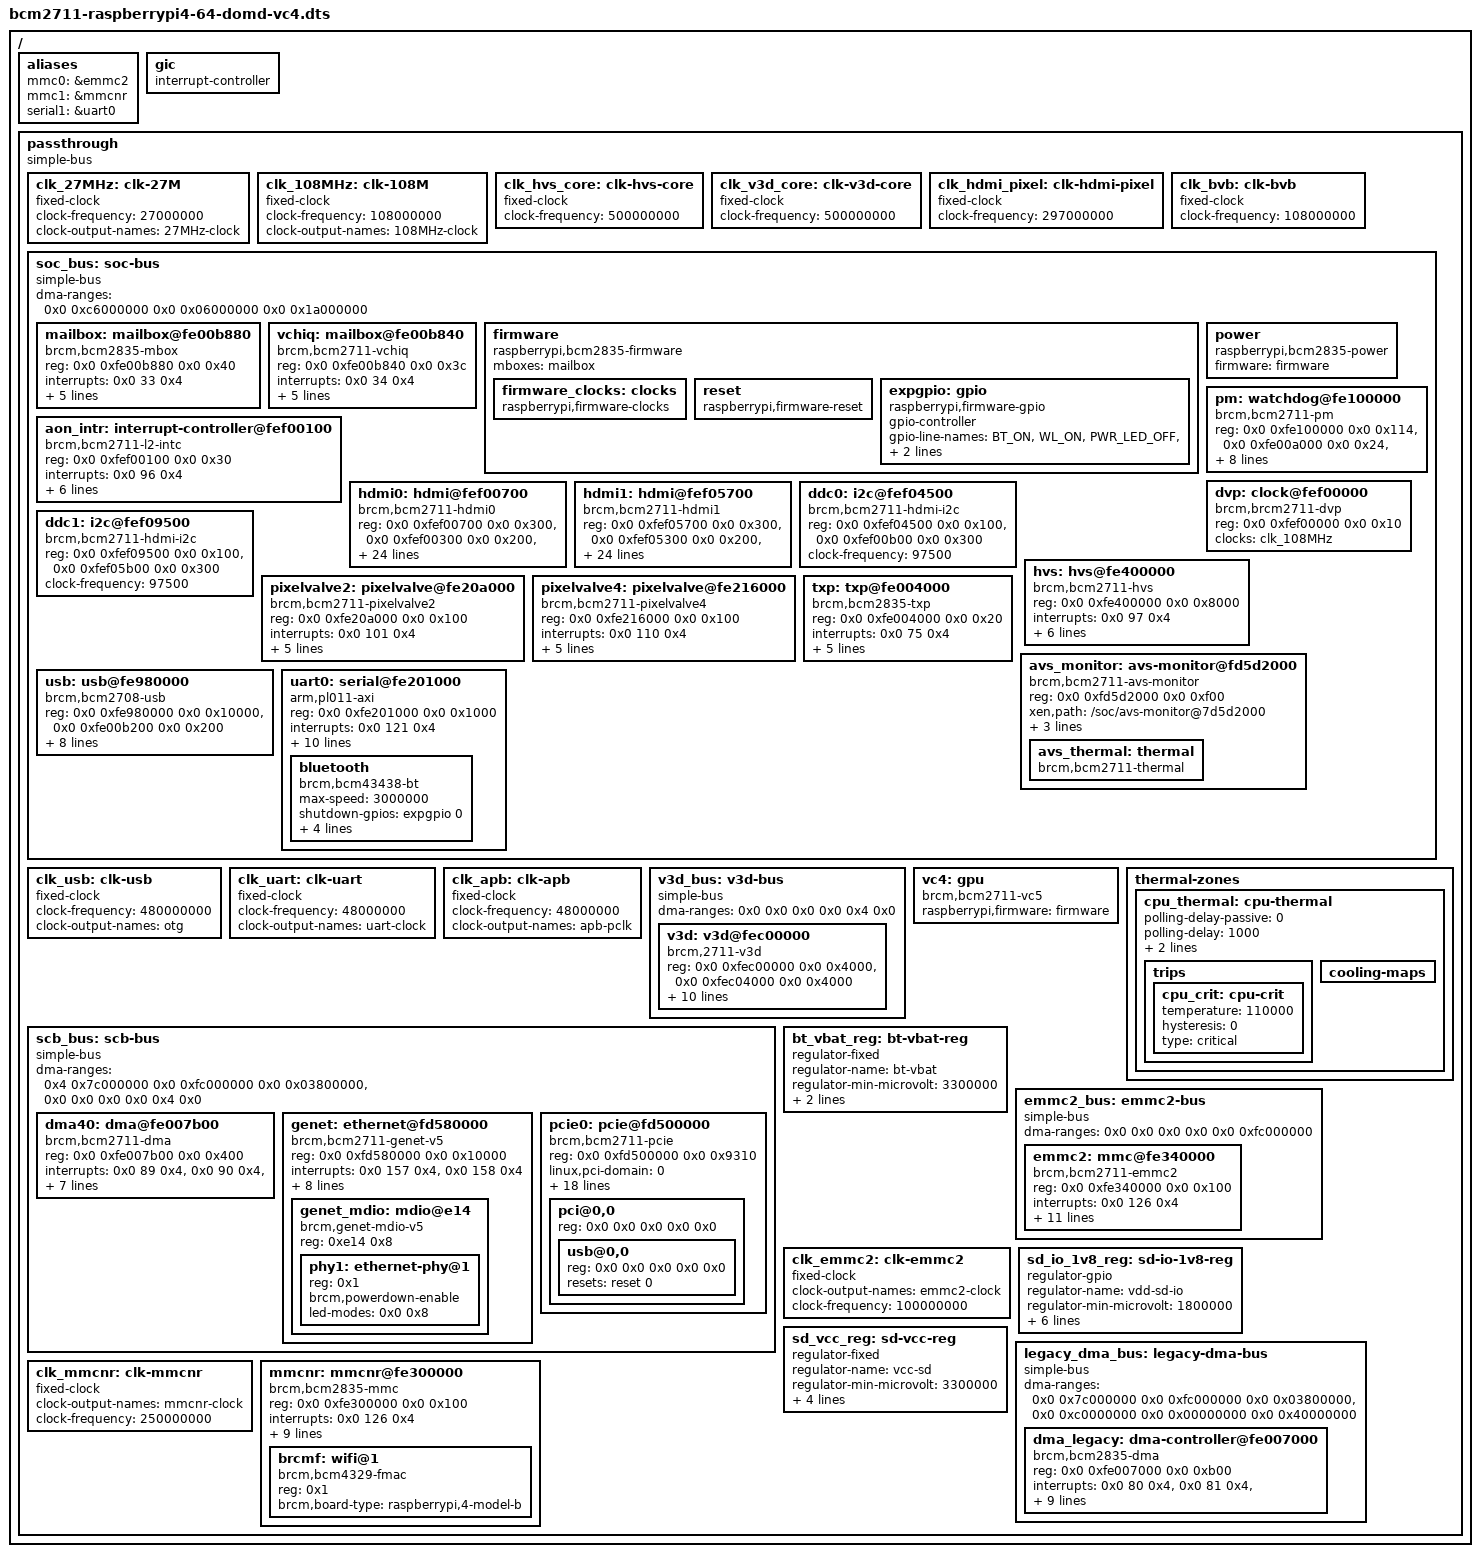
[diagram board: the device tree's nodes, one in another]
/*
 * BCM2711 / Raspberry Pi 4 — DomD (vc4 driver domain) partial device tree
 *
 * Copyright (c) 2026 Yuichi Kusakabe
 *
 * SPDX-License-Identifier: Apache-2.0
 *
 * Architecture: control Dom0 (Zephyr or thin Linux) + dom0less direct-mapped
 * DomD that owns the whole display/GPU complex, and — in the Zephyr flavour —
 * the SD controller as well.
 *
 * ===========================================================================
 * Source of truth
 * ===========================================================================
 * Every address, size and GIC SPI below was read out of the shipped
 * bcm2711-rpi-4-b.dtb (see ../../../../BCM2711-DT-TRUTH.md), NOT translated
 * from the BCM2712 version. Bus translation applied:
 *   /soc      1/1  0x7e000000 -> 0xfe000000, 0x7c000000 -> 0xfc000000,
 *                  0x40000000 -> 0xff800000
 *   /emmc2bus 2/1  0x7e000000 -> 0xfe000000
 *   /scb      2/2  0x7c000000 -> 0xfc000000 (so 0x7d500000 -> 0xfd500000)
 *   /v3dbus   1/2  0x7c500000 -> 0xfc500000 (so 0x7ec00000 -> 0xfec00000)
 * BCM2711 is a 35-bit map and every MMIO block lands below 4 GiB, so all
 * addresses here are plain 32-bit values in 2-cell form — none of the BCM2712
 * `0x10_7c......` 40-bit forms remain.
 *
 * ===========================================================================
 * xen,reg / xen,path rules honoured here (xen/common/device-tree/dom0less-build.c)
 * ===========================================================================
 *  - xen,reg = <host_pbase size guest_gbase>, ALL page-aligned. Identity
 *    mapping (guest IPA == host PA) because DomD is direct-map.
 *  - a node with xen,path MUST also have xen,reg (else -EINVAL), and the IRQs
 *    of the *host* node named by xen,path are what get routed to DomD.
 *  - every host page is mapped exactly ONCE across the whole partial DT, with
 *    TWO deliberate exceptions: page 0xfe00b000, declared identically by
 *    mailbox@fe00b880 and by vchiq (mailbox@fe00b840), and page 0xfe007000,
 *    declared identically by the legacy DMA engine (dma-controller@fe007000)
 *    and by dma40 (dma@fe007b00).
 *    Single ownership is OUR rule, not Xen's: a duplicate xen,reg does not fail,
 *    because map_regions_p2mt() -> p2m_insert_mapping() -> p2m_set_entry()
 *    (xen/arch/arm/p2m.c:113) overwrites the existing entry. It matters because a
 *    page mapped twice usually means two nodes each believe they own it, and the
 *    second one's intent is silently discarded. Devices sharing a 4 KiB page are
 *    therefore represented as one "owner" node carrying xen,path+xen,reg plus
 *    plain sibling nodes with no xen,* properties at all.
 *    Both exceptions are forced rather than chosen: each second node has GIC
 *    SPIs OF ITS OWN (vchiq 34 against the firmware mailbox's 33; dma40 89-92
 *    against the legacy engine's 80-88), Xen routes a node's IRQs only from
 *    the xen,path branch of handle_passthrough_prop(), and its caller rejects a
 *    xen,path without xen,reg with -EINVAL, which panics domain construction.
 *    There is no way to say "route the IRQ, the MMIO is already mapped". See the
 *    note on vchiq's xen,reg for why repeating the mapping is safe.
 *  - IRQs whose interrupt-parent is not the GIC are skipped by Xen
 *    (map_interrupts_to_domain), so the HDMI L2 sub-IRQs need no GIC grant —
 *    only their L2 parent (aon_intr, GIC SPI 96) does.
 *
 * ===========================================================================
 * DMA: the central BCM2711 difference
 * ===========================================================================
 * BCM2711 has no IOMMU and its legacy peripherals address DRAM through the
 * VideoCore bus alias at 0xc0000000, limited to the low 1 GiB. Read the values
 * from the RUNNING tree, not from bcm2711-rpi-4-b.dtb: the firmware rewrites
 * some of them before boot (`fdt print /soc` / `/emmc2bus` at the U-Boot
 * prompt). What the two look like on a 4 GiB board:
 *     /soc      dma-ranges = <0xc0000000 0x0 0x0 0x40000000>   (alias, low 1 GiB)
 *                            <0x7c000000 0x0 0xfc000000 0x3800000>
 *     /emmc2bus dma-ranges = <0x0 0x0 0x0 0x0 0xfc000000>      (IDENTITY, 3.94 GiB)
 * The file ships <0x0 0xc0000000 0x0 0x0 0x40000000> for /emmc2bus; the
 * firmware replaces it. So a dma_addr handed to the VideoCore or the HVS must
 * be (phys + 0xc0000000) with phys < 1 GiB, but one handed to emmc2 is the
 * plain physical address -- see the note at emmc2_bus below for what carrying
 * the pre-fixup alias to emmc2 did on hardware. GENET (/scb, 16 GiB) and V3D
 * (/v3dbus, own MMU) are identity-mapped and unrestricted.
 *
 * That is modelled with four intermediate simple-bus wrappers, each carrying
 * only the dma-ranges its children need (MMIO stays identity via `ranges;`):
 *     soc_bus                ->  <0x0 0xc6000000  0x0 0x06000000  0x0 0x1a000000>
 *                                bus 0xc6000000 == phys 0x06000000, 416 MiB
 *     emmc2_bus              ->  <0x0 0x0  0x0 0x0  0x0 0xfc000000>
 *                                identity, as the firmware-fixed host DT has it
 *     legacy_dma_bus         ->  <0x0 0x7c000000  0x0 0xfc000000  0x0 0x03800000>,
 *                                <0x0 0xc0000000  0x0 0x00000000  0x0 0x40000000>
 *                                the host /soc pair verbatim: peripherals as the
 *                                VideoCore sees them, plus the DRAM alias
 *     scb_bus   / v3d_bus    ->  identity
 * 0x06000000+0x1a000000 covers DomD static-mem bank1 on both SKUs, the only DomD
 * RAM the VideoCore can see: it IS bank1 on the 4 GiB map (set by the boot
 * script's board_ram block) and contains the 8 GiB map's 0x08000000+384 MiB
 * (bcm2711-raspberrypi4-64-xen.dtso). Only the start moved down; the end, and
 * with it the tree minimum in (a) below, is still 0x20000000.
 * legacy_dma_bus is a bus of its own rather than a second dma-ranges entry on
 * soc_bus because of_dma_get_max_cpu_address() takes the MAXIMUM of cpu_addr+size
 * WITHIN a node but the MINIMUM ACROSS nodes: this bus's own maximum is
 * 0xff7fffff, higher than soc_bus's 0x1fffffff, so the tree minimum -- and with it
 * consequence (a) below -- does not move. Widening soc_bus instead would move it
 * and would break scanout.
 *
 * Two consequences we rely on:
 *   a) of_dma_get_max_cpu_address() takes the MINIMUM dma-ranges limit found
 *      anywhere in the tree, so arm64_dma_phys_limit becomes 0x20000000 and
 *      dma_contiguous_reserve() places vc4's CMA inside bank1 automatically.
 *      No `cma=<n>@<addr>` pinning is required — only `cma=<n>`.
 *   b) vc4_drm_bind() does not use its own node's DMA properties: it calls
 *      of_dma_configure(dev, node, true) on the first node matching
 *      vc4_dma_range_matches[], and on BCM2711 the only entry present is
 *      "brcm,bcm2711-hvs". So the DRM device — and therefore every dumb/CMA
 *      buffer object weston allocates — inherits the dma-ranges of whatever
 *      bus the HVS node sits under. Keeping hvs inside soc_bus is what makes
 *      display buffers land in the VideoCore-reachable window with the correct
 *      0xc0000000 bus alias; moving it out would silently break scanout.
 *
 * NOTE on 3D: on BCM2711 vc4_v3d_dt_match[] does NOT list "brcm,2711-v3d", so
 * vc4 is display-only here (no DRIVER_RENDER) and the separate drivers/gpu/drm/
 * v3d driver owns the 3D core, exposing renderD128 alongside vc4's card0. That
 * matches native RPi4 and is what Mesa expects.
 * ===========================================================================
 */

/dts-v1/;

/ {
	#address-cells = <0x2>;
	#size-cells = <0x2>;

	/*
	 * Root-level /gic and /hypervisor are NOT copied into the guest DT:
	 * domain_handle_dtb_boot_module() only scans the partial DT's `aliases`
	 * and `passthrough` nodes. They exist purely so dtc can resolve the
	 * <&gic> references inside /passthrough at build time.
	 *
	 * The phandle is hard-coded to GUEST_PHANDLE_GIC (65000 = 0xfde8) from
	 * xen/include/public/device_tree_defs.h because THIS FRAGMENT IS ALSO
	 * MEANT FOR libxl: a domd.cfg names it in `device_tree =` (this board
	 * installs none; README "No domd.cfg on this board"), and libxl gives
	 * the GIC node it generates a hard-coded GUEST_PHANDLE_GIC
	 * (libxl_arm.c make_gicv{2,3}_node()). A lower value would leave every
	 * interrupt-parent inside /passthrough pointing at a non-existent node
	 * on that path -> no IRQs in DomD -> vc4-drm never binds.
	 *
	 * On the dom0less path the value is NOT required to be 65000: Xen reads
	 * it back from this node (init_intc_phandle()) and gives its generated
	 * vGIC the same phandle -- GUEST_PHANDLE_GIC is merely the default
	 * prepare_dtb_domU() starts from. Xen 4.22 then REJECTS a fragment whose
	 * highest phandle is in the reserved range ("Device tree generation
	 * failed (-75)", panic, reboot loop); that is an upstream regression
	 * fixed here by xen patch 4.22-0006, not a reason to change this value.
	 */
	/*
	 * serial1 = the REAL pl011, so that Xen's emulated vpl011 keeps ttyAMA0 —
	 * which is what DomD's bootargs say (console=ttyAMA0).
	 *
	 * DomD ends up with two pl011-family ports: Xen's vpl011, which appears in
	 * the generated guest DT as /sbsa-uart@<base> with compatible
	 * "arm,sbsa-uart" (xen/arch/arm/dom0less-build.c:181-185), and the physical
	 * one below. Both are handled by amba-pl011.c and both allocate out of the
	 * same amba_ports[] array, so without a hint the index is
	 * first-come-first-served.
	 *
	 * pl011_setup_port() calls pl011_probe_dt_alias() (amba-pl011.c:2780-2809),
	 * which honours a "serialN" alias and falls back to the caller's index
	 * otherwise. sbsa_uart_probe() has no alias entry, so it takes
	 * pl011_find_free_port() = the lowest free slot. Pinning the physical port to
	 * 1 therefore gives vpl011 slot 0 in either probe order. Measured on the
	 * board: the physical port comes up as ttyAMA1 and hci0 binds under
	 * fe201000.serial, while DomD's console stays on ttyAMA0. (An "aliased and
	 * non-aliased serial devices" warning is expected and harmless.)
	 *
	 * Xen copies this node across: domain_handle_dtb_boot_module() scans exactly
	 * `aliases` and `passthrough` in the partial DT. dtc turns the &label into
	 * the node's full path string.
	 *
	 * &uart0 lives OUTSIDE the SD-STRIP block near the end of this file, so this
	 * reference survives the DOM0_OS=linux strip.
	 */
	aliases {
		/* SODEV-LINUX-DOM0-SD-STRIP-BEGIN: these TWO LINES ONLY.
		 * Pin the mmc host index. Linux assigns it in mmc_alloc_host() from
		 * of_alias_get_id(dev->of_node, "mmc") and only falls back to
		 * first-come-first-served when there is no alias. DomD boots with
		 * root=/dev/mmcblk0p2, so emmc2 MUST be mmc0; without this the mmcnr
		 * below probes first, takes index 0, the SD card slides to mmcblk1 and
		 * `rootwait` waits forever with no error printed:
		 *
		 *     mmc0: SDHCI controller on fe300000.mmcnr ... using PIO
		 *     mmc1: SDHCI controller on fe340000.mmc ... using ADMA
		 *     mmcblk1: mmc1:d555 ST512 456 GiB
		 *     Waiting for root device /dev/mmcblk0p2...
		 *
		 * The host DT pins the same two (mmc0 = /emmc2bus/mmc@7e340000,
		 * mmc1 = /soc/mmcnr@7e300000); this mirrors it.
		 *
		 * &emmc2 and &mmcnr are both declared inside the big SD-STRIP block near
		 * the end of this file, so for DOM0_OS=linux domd-vc4.bb deletes the
		 * nodes and these two references would be left dangling. dtc then
		 * refuses the whole tree --
		 *     ERROR (path_references): /aliases: Reference to non-existent node
		 *                              or label "emmc2"
		 * -- and do_compile produces no DTB at all.
		 *
		 * JUST these two lines are marked, and NOT the whole /aliases node:
		 * serial1 below points at &uart0, which lives outside the strip block
		 * and is load-bearing for Bluetooth. domd-vc4.bb's sed is
		 * `/BEGIN/,/END/d`, which deletes EVERY BEGIN..END range it finds, so a
		 * second pair here needs no recipe change. Comments are dropped by dtc,
		 * so the zephyr DTB is unaffected by the markers themselves.
		 */
		mmc0 = &emmc2;
		mmc1 = &mmcnr;
		/* SODEV-LINUX-DOM0-SD-STRIP-END */
		serial1 = &uart0;
	};

	gic: gic {
		#interrupt-cells = <0x3>;
		interrupt-controller;
		phandle = <0xfde8>;
		linux,phandle = <0xfde8>;
	};

	passthrough: passthrough {
		/*
		 * The Xen partial-DT spec (xen/docs/misc/arm/passthrough.txt)
		 * mandates compatible="simple-bus" here; Linux's
		 * of_platform_default_populate() also needs it to enumerate the
		 * children as platform devices.
		 */
		compatible = "simple-bus";
		ranges;
		#address-cells = <0x2>;
		#size-cells = <0x2>;

		/* ==============================================================
		 * Fixed clocks (root-level on the host DT; the partial-DT spec
		 * allows them under /passthrough because they have no MMIO).
		 * ============================================================== */
		clk_27MHz: clk-27M {
			compatible = "fixed-clock";
			#clock-cells = <0>;
			clock-frequency = <27000000>;
			clock-output-names = "27MHz-clock";
		};

		clk_108MHz: clk-108M {
			compatible = "fixed-clock";
			#clock-cells = <0>;
			clock-frequency = <108000000>;
			clock-output-names = "108MHz-clock";
		};

		/*
		 * Fallback fixed-clocks for the display path. NOT wired by
		 * default: unlike BCM2712 (where raspberrypi-clk probe failed
		 * with -22 and the RPi5 port had to fake every clock), BCM2711
		 * natively drives HVS/V3D/HDMI from <&firmware_clocks N> and the
		 * mbox-bus dma-ranges above is what makes that work inside DomD.
		 * If `raspberrypi-clk` still fails on hardware, swap the
		 * <&firmware_clocks N> references below for these and re-test —
		 * that is the whole fallback, no other change needed.
		 */
		clk_hvs_core: clk-hvs-core {
			compatible = "fixed-clock";
			#clock-cells = <0>;
			clock-frequency = <500000000>;
		};
		clk_v3d_core: clk-v3d-core {
			compatible = "fixed-clock";
			#clock-cells = <0>;
			clock-frequency = <500000000>;
		};
		clk_hdmi_pixel: clk-hdmi-pixel {
			compatible = "fixed-clock";
			#clock-cells = <0>;
			clock-frequency = <297000000>;
		};
		clk_bvb: clk-bvb {
			compatible = "fixed-clock";
			#clock-cells = <0>;
			clock-frequency = <108000000>;
		};

		/* ==============================================================
		 * soc_bus — every /soc device DomD owns.
		 *
		 * dma-ranges gives the VideoCore bus alias (phys + 0xc0000000)
		 * bounded to DomD static-mem bank1 (0x06000000 + 416 MiB on the
		 * 4 GiB map; the 8 GiB map's bank1 is the top 384 MiB of it), the
		 * only DomD RAM below the 1 GiB VideoCore DMA limit. This is the
		 * RPi4 equivalent of the RPi5 "mbox-bus" fix, but it now also
		 * covers HVS (display fetch) and — via emmc2_bus — the SD
		 * controller, because on BCM2711 all three share the same
		 * restriction.
		 * ============================================================== */
		soc_bus: soc-bus {
			compatible = "simple-bus";
			#address-cells = <0x2>;
			#size-cells = <0x2>;
			ranges;
			dma-ranges = <0x0 0xc6000000 0x0 0x06000000 0x0 0x1a000000>;

			/* ---- VideoCore mailbox + firmware interface ---- */
			mailbox: mailbox@fe00b880 {
				compatible = "brcm,bcm2835-mbox";
				reg = <0x0 0xfe00b880 0x0 0x40>;
				interrupts = <0x0 33 0x4>;	/* GIC SPI 33 LEVEL_HIGH */
				interrupt-parent = <&gic>;
				#mbox-cells = <0>;
				xen,path = "/soc/mailbox@7e00b880";
				xen,force-assign-without-iommu;
				/*
				 * Page 0xfe00b000 also holds mailbox@7e00b840
				 * (vchiq) and the dwc2 controller's second reg
				 * block (0xfe00b200), so this one mapping covers
				 * all three; usb@fe980000 below must NOT map it
				 * again. vchiq below DOES repeat it, deliberately
				 * and identically -- see the note on its xen,reg.
				 */
				xen,reg = <0x0 0xfe00b000 0x0 0x1000 0x0 0xfe00b000>;
				status = "okay";
			};

			/* ------------------------------------------------------------------
			 * vchiq -- the VideoCore host interface the H.264 decoder rides on.
			 *
			 * WHY IT IS HERE
			 * The only H.264 decode hardware reachable on BCM2711 is inside
			 * VideoCore, driven through VCHIQ/MMAL by bcm2835-codec, which
			 * presents a V4L2 M2M decoder. Without this node vchiq never binds
			 * (CONFIG_BCM2835_VCHIQ=y, so it waits for the DT node, not for a
			 * module), bcm2835-codec has nothing to talk to, no /dev/videoN
			 * appears, and the virtio-media device DomA is given has no backend.
			 * It also needs dma40 on scb_bus: on BCM2711 vchiq fails its probe
			 * without a brcm,bcm2711-dma node (see there).
			 *
			 * The dedicated codec@7eb10000 block is HEVC-only and is deliberately
			 * NOT added here: nothing on this product decodes HEVC (the guest's
			 * decoder list is H.264 only), so it would be a node added for no user.
			 *
			 * The RPi5 has no vchiq node at all, which is why H.264 hardware
			 * decode is RPi4-only on this platform.
			 *
			 * DELTAS FROM THE HOST NODE /soc/mailbox@7e00b840
			 *
			 *   pinctrl-0   Dropped. The host points at <&audio_pins> under
			 *               gpio@7e200000 -- GPIO 40/41 muxed to ALT0, i.e. the
			 *               analog PWM audio on the headphone jack. That has
			 *               nothing to do with the mailbox transport this node is
			 *               here for, DomA's audio goes out over HDMI, and DomD
			 *               has no GPIO controller to apply it with.
			 *
			 *   xen,reg     Identical to the mailbox node's above, ON PURPOSE.
			 *               vchiq's registers (0xfe00b840 + 0x3c) sit in the same
			 *               4 KiB page as the mailbox's, and there is no way to
			 *               say "route the IRQ, the MMIO is already mapped":
			 *               handle_passthrough_prop()'s caller rejects a
			 *               xen,path without xen,reg with -EINVAL, and -EINVAL
			 *               there panics domain construction. Repeating the same
			 *               mapping is safe on both counts the code cares about:
			 *               map_regions_p2mt() ends in p2m_set_entry(), which
			 *               overwrites an identical GFN->MFN entry rather than
			 *               rejecting it, and the rangeset that tracks assigned
			 *               guest ranges returns 0 for a range already contained
			 *               -- that rangeset only feeds the memory-hole
			 *               subtraction which keeps guest RAM off passthrough
			 *               MMIO, so a duplicate is a no-op there. An empty
			 *               xen,reg would also skip the mapping loop, but only
			 *               because the length computes to 0 -- an unintended
			 *               hole that one upstream length check would turn into a
			 *               panic. If the duplicate is ever refused, Xen says so
			 *               out loud with "Failed to map", which is worth more
			 *               than a quiet trick.
			 *
			 * GIC SPI 34 is this node's alone -- no other host node names it, so
			 * unlike mmcnr/emmc2 on SPI 126 there is no shared-line hazard here.
			 *
			 * The host side needs the matching release: &vchiq in
			 * bcm2711-raspberrypi4-64-xen.dtso. The label `mailbox` resolves to
			 * /soc/mailbox@7e00b880, the FIRMWARE mailbox on SPI 33, and does not
			 * cover this node.
			 * ------------------------------------------------------------------ */
			vchiq: mailbox@fe00b840 {
				compatible = "brcm,bcm2711-vchiq";
				reg = <0x0 0xfe00b840 0x0 0x3c>;
				interrupts = <0x0 34 0x4>;	/* GIC SPI 34 LEVEL_HIGH */
				interrupt-parent = <&gic>;
				xen,path = "/soc/mailbox@7e00b840";
				xen,force-assign-without-iommu;
				xen,reg = <0x0 0xfe00b000 0x0 0x1000 0x0 0xfe00b000>;
				status = "okay";
			};

			firmware: firmware {
				compatible = "raspberrypi,bcm2835-firmware", "simple-mfd";
				#address-cells = <0x1>;
				#size-cells = <0x1>;
				mboxes = <&mailbox>;

				firmware_clocks: clocks {
					compatible = "raspberrypi,firmware-clocks";
					#clock-cells = <0x1>;
				};

				/*
				 * raspberrypi,firmware-reset provides the VL805
				 * xHCI reset (RASPBERRYPI_FIRMWARE_RESET_ID_USB
				 * = 0) that pci@0,0/usb@0,0 needs to make the
				 * firmware reload the VL805 SPI firmware.
				 */
				reset: reset {
					compatible = "raspberrypi,firmware-reset";
					#reset-cells = <0x1>;
				};

				/*
				 * expgpio drives the SD card power / IO-voltage
				 * regulators (sd_vcc_reg / sd_io_1v8_reg) that
				 * emmc2 depends on in the Zephyr flavour.
				 */
				expgpio: gpio {
					compatible = "raspberrypi,firmware-gpio";
					gpio-controller;
					#gpio-cells = <0x2>;
					gpio-line-names = "BT_ON", "WL_ON",
							  "PWR_LED_OFF",
							  "GLOBAL_RESET",
							  "VDD_SD_IO_SEL",
							  "CAM_GPIO",
							  "SD_PWR_ON",
							  "SD_OC_N";
					status = "okay";
				};
			};

			/*
			 * raspberrypi,bcm2835-power — the firmware-backed power
			 * domain provider (host phandle "power", NOT "pm").
			 * dwc2 references <&power 6> (RPI_POWER_DOMAIN_USB).
			 * No MMIO, so no xen,reg is needed.
			 */
			power: power {
				compatible = "raspberrypi,bcm2835-power";
				firmware = <&firmware>;
				#power-domain-cells = <0x1>;
			};

			/*
			 * ---- bcm2835-pm: V3D power domain + reset ----
			 * The host V3D node uses power-domains = <&pm 1>
			 * (BCM2835_POWER_DOMAIN_GRAFX_V3D) and resets =
			 * <&pm 0> (BCM2835_RESET_V3D), both provided by
			 * /soc/watchdog@7e100000. Passing it through is what
			 * actually powers the 3D core: leaving it out makes
			 * dev_pm_domain_attach() defer v3d's probe forever, and
			 * dropping the property instead makes v3d_drv fall back
			 * to requiring a "bridge" reg block that BCM2711 does
			 * not have. The display path (HVS/PV/HDMI) has no power
			 * domain on BCM2711 and is unaffected either way.
			 *
			 * Three separate host pages: pm 0xfe100000,
			 * asb 0xfe00a000, rpivid_asb 0xfec11000.
			 */
			pm: watchdog@fe100000 {
				compatible = "brcm,bcm2711-pm", "brcm,bcm2835-pm-wdt";
				#power-domain-cells = <0x1>;
				#reset-cells = <0x1>;
				reg = <0x0 0xfe100000 0x0 0x114>,
				      <0x0 0xfe00a000 0x0 0x24>,
				      <0x0 0xfec11000 0x0 0x20>;
				reg-names = "pm", "asb", "rpivid_asb";
				/*
				 * bcm2835-power fetches its clocks with
				 * devm_clk_get_optional(dev->parent, name), so
				 * peri_image/h264/isp may simply be absent —
				 * DomD drives neither the codecs nor the ISP,
				 * and providing them would mean pulling cprman
				 * (and its clk-osc + dsi0/dsi1 PHY clock
				 * providers) into the driver domain for nothing.
				 * Only "v3d" is wired, from the firmware clock.
				 */
				clocks = <&firmware_clocks 5>;
				clock-names = "v3d";
				/*
				 * Deliberately NO system-power-controller: the
				 * host node has it, but a driver domain must not
				 * be able to reset the whole board.
				 */
				xen,path = "/soc/watchdog@7e100000";
				xen,force-assign-without-iommu;
				xen,reg = <0x0 0xfe100000 0x0 0x1000 0x0 0xfe100000>,
					  <0x0 0xfe00a000 0x0 0x1000 0x0 0xfe00a000>,
					  <0x0 0xfec11000 0x0 0x1000 0x0 0xfec11000>;
				status = "okay";
			};

			/*
			 * ---- Display/HDMI L2 interrupt controller ----
			 * BCM2711 has exactly ONE L2 controller in the display
			 * area (/soc/interrupt-controller@7ef00100, host label
			 * "aon_intr"), GIC SPI 96, LEVEL_HIGH. BCM2712's
			 * disp_intr / bsc_irq / mop / moplet have no BCM2711
			 * equivalent, and BCM2711's HVS is wired straight to the
			 * GIC instead.
			 *
			 * The type is LEVEL_HIGH, matching mainline Linux (which
			 * has said so since at least v5.19) and raspberrypi/linux
			 * from rpi-6.1.y onwards, including the 6.18 pinned here.
			 * It is NOT edge, despite what the bcm2711-rpi-4-b.dtb
			 * that raspberrypi/firmware distributes still says: that
			 * prebuilt carries the pre-6.1 EDGE_RISING value and is
			 * simply stale. rpi-5.10.y/5.15.y had EDGE_RISING too.
			 *
			 * This is load-bearing, measured on hardware 2026-09-02.
			 * The brcmstb-l2 driver masks all 32 child sources and
			 * clears their status at the top of its probe, so the
			 * controller's output line is low by the time it chains
			 * the parent. With a level type that means no pending
			 * parent and the probe finishes quietly. With an edge
			 * type a rising edge latched earlier -- during the
			 * firmware's HDMI/EDID work, before Linux runs -- stays
			 * pending regardless of the line, gets re-sent the moment
			 * irq_set_chained_handler_and_data() starts the parent,
			 * and DomD dies in an initcall with
			 *   brcmstb_l2_intc_irq_handle+0x40
			 *   Kernel panic: Fatal exception in interrupt
			 * (the handler's first dereference happens before the
			 * driver assigns data->gc; see the 0013 patch in
			 * meta-xt-driver-domain, which closes that window too).
			 *
			 * aon_intr owns the 0xfef00000 page, which also contains
			 * dvp (0xfef00000), the HDMI0 csc/dvp/hdmi/phy/rm blocks
			 * and HDMI1's csc — so it is the single xen,reg owner and
			 * gets SPI 96 routed to DomD.
			 */
			aon_intr: interrupt-controller@fef00100 {
				compatible = "brcm,bcm2711-l2-intc", "brcm,l2-intc";
				reg = <0x0 0xfef00100 0x0 0x30>;
				interrupts = <0x0 96 0x4>;	/* GIC SPI 96 LEVEL_HIGH */
				interrupt-parent = <&gic>;
				interrupt-controller;
				#interrupt-cells = <0x1>;
				xen,path = "/soc/interrupt-controller@7ef00100";
				xen,force-assign-without-iommu;
				xen,reg = <0x0 0xfef00000 0x0 0x1000 0x0 0xfef00000>;
				status = "okay";
			};

			/*
			 * dvp = "Display VPU" clock + reset provider
			 * (brcm,brcm2711-dvp). Supplies the HDMI "audio" clock
			 * (<&dvp 0|1>) and the HDMI resets. Its 0x10 bytes at
			 * 0xfef00000 are inside aon_intr's page and it has no
			 * interrupts, so it carries no xen,* properties.
			 */
			dvp: clock@fef00000 {
				compatible = "brcm,brcm2711-dvp";
				reg = <0x0 0xfef00000 0x0 0x10>;
				clocks = <&clk_108MHz>;
				#clock-cells = <0x1>;
				#reset-cells = <0x1>;
				status = "okay";
			};

			/*
			 * ---- HDMI0 -> micro-HDMI-A-1 (DomU cluster) ----
			 * All ten host reg blocks, in the host order, so
			 * reg-names line up with vc4_hdmi's expectations
			 * (vc5_hdmi_init_resources also needs "intr2").
			 *
			 * Pages: hdmi/dvp/phy/rm/csc are inside aon_intr's
			 * 0xfef00000 page; this node therefore only maps
			 * 0xfef01000+0x2000 (packet at +0x1b00 and metadata
			 * at +0x1f00 size 0x400, which spills over into
			 * 0xfef02000 -- two pages, not one), 0xfef04000
			 * (cec + ddc0's bsc) and the shared 0xfef20000 (hd).
			 * `dmas`/`dma-names` carry HDMI audio: DomA (AAOS) plays
			 * out of HDMI through qemu's virtio-snd, which opens
			 * DomD's vc4hdmi ALSA card, so the 40-bit DMA controller
			 * the host routes them to is passed through (dma40 on
			 * scb_bus).
			 *
			 * Why this is the load-bearing property:
			 * vc4_hdmi_audio_init() (drivers/gpu/drm/vc4/vc4_hdmi.c:2263)
			 *     if (!of_find_property(dev->of_node, "dmas", &len) || !len) {
			 *             dev_warn(dev, "'dmas' DT property is missing or
			 *                      empty, no HDMI audio\n");
			 *             return 0;
			 *     }
			 * returns 0, so vc4 probes fine and DISPLAY WORKS; only the
			 * ASoC card is silently not registered, with one dev_warn.
			 *
			 * The DREQ numbers and flag bits are the host DTB's values,
			 * verbatim: bcm2711-rpi-4-b.dtb has dmas = <&dma40 0x41fa000a>
			 * on HDMI0 and 0x41fa0011 on HDMI1. Written in the same
			 * decomposed form as meta-xt-rpi5's bcm2712-raspberrypi5-hdmi.dtso,
			 * which evaluates bit-for-bit to those constants:
			 *     10|(1<<30)|(1<<24)|(10<<16)|(15<<20) == 0x41fa000a
			 * (bit30 = 40-bit addressing; bit24 and the two nibble fields
			 * are the burst/panic thresholds).
			 */
			hdmi0: hdmi@fef00700 {
				compatible = "brcm,bcm2711-hdmi0";
				reg = <0x0 0xfef00700 0x0 0x300>,
				      <0x0 0xfef00300 0x0 0x200>,
				      <0x0 0xfef00f00 0x0 0x80>,
				      <0x0 0xfef00f80 0x0 0x80>,
				      <0x0 0xfef01b00 0x0 0x200>,
				      <0x0 0xfef01f00 0x0 0x400>,
				      <0x0 0xfef00200 0x0 0x80>,
				      <0x0 0xfef04300 0x0 0x100>,
				      <0x0 0xfef20000 0x0 0x100>,
				      <0x0 0xfef00100 0x0 0x30>;
				reg-names = "hdmi", "dvp", "phy", "rm",
					    "packet", "metadata", "csc",
					    "cec", "hd", "intr2";
				clocks = <&firmware_clocks 13>,
					 <&firmware_clocks 14>,
					 <&dvp 0>,
					 <&clk_27MHz>;
				clock-names = "hdmi", "bvb", "audio", "cec";
				resets = <&dvp 0>;
				/*
				 * vc4_hdmi.c:3229 in the kernel this build ships
				 * parses ONLY "ddc"
				 * (of_parse_phandle(dev->of_node, "ddc", 0)).
				 * "ddc-i2c-bus" is not read by any driver in this
				 * tree — the claim that "upstream mainline parses
				 * ddc-i2c-bus" was not verified against it. The
				 * extra property is harmless (an unknown property
				 * is ignored) and is kept only so the node stays
				 * copy-pastable to a kernel that wants that name.
				 */
				ddc = <&ddc0>;
				ddc-i2c-bus = <&ddc0>;
				interrupt-parent = <&aon_intr>;
				interrupts = <0>, <1>, <2>, <3>, <4>, <5>;
				interrupt-names = "cec-tx", "cec-rx", "cec-low",
						  "wakeup", "hpd-connected",
						  "hpd-removed";
				wifi-2.4ghz-coexistence;
				dmas = <&dma40 (10|(1<<30)|(1<<24)|(10<<16)|(15<<20))>;
				dma-names = "audio-rx";
				xen,path = "/soc/hdmi@7ef00700";
				xen,force-assign-without-iommu;
				xen,reg = <0x0 0xfef01000 0x0 0x2000 0x0 0xfef01000>,
					  <0x0 0xfef04000 0x0 0x1000 0x0 0xfef04000>,
					  <0x0 0xfef20000 0x0 0x1000 0x0 0xfef20000>;
				status = "okay";
			};

			/* ---- HDMI1 -> micro-HDMI-A-2 (DomA / AAOS) ---- */
			hdmi1: hdmi@fef05700 {
				compatible = "brcm,bcm2711-hdmi1";
				reg = <0x0 0xfef05700 0x0 0x300>,
				      <0x0 0xfef05300 0x0 0x200>,
				      <0x0 0xfef05f00 0x0 0x80>,
				      <0x0 0xfef05f80 0x0 0x80>,
				      <0x0 0xfef06b00 0x0 0x200>,
				      <0x0 0xfef06f00 0x0 0x400>,
				      <0x0 0xfef00280 0x0 0x80>,
				      <0x0 0xfef09300 0x0 0x100>,
				      <0x0 0xfef20000 0x0 0x100>,
				      <0x0 0xfef00100 0x0 0x30>;
				reg-names = "hdmi", "dvp", "phy", "rm",
					    "packet", "metadata", "csc",
					    "cec", "hd", "intr2";
				clocks = <&firmware_clocks 13>,
					 <&firmware_clocks 14>,
					 <&dvp 1>,
					 <&clk_27MHz>;
				clock-names = "hdmi", "bvb", "audio", "cec";
				resets = <&dvp 1>;
				ddc = <&ddc1>;
				ddc-i2c-bus = <&ddc1>;
				interrupt-parent = <&aon_intr>;
				interrupts = <8>, <7>, <6>, <9>, <10>, <11>;
				interrupt-names = "cec-tx", "cec-rx", "cec-low",
						  "wakeup", "hpd-connected",
						  "hpd-removed";
				wifi-2.4ghz-coexistence;
				dmas = <&dma40 (17|(1<<30)|(1<<24)|(10<<16)|(15<<20))>;
				dma-names = "audio-rx";
				xen,path = "/soc/hdmi@7ef05700";
				xen,force-assign-without-iommu;
				/*
				 * hd (0xfef20000) is already mapped by hdmi0 —
				 * re-mapping the same host page would fail, so
				 * only HDMI1's own pages are listed here.
				 */
				xen,reg = <0x0 0xfef05000 0x0 0x1000 0x0 0xfef05000>,
					  <0x0 0xfef06000 0x0 0x2000 0x0 0xfef06000>,
					  <0x0 0xfef09000 0x0 0x1000 0x0 0xfef09000>;
				status = "okay";
			};

			/*
			 * ---- HDMI DDC (EDID readback) ----
			 * brcm,bcm2711-hdmi-i2c needs no clocks and no IRQ on
			 * BCM2711 (it polls). status must be "okay" or
			 * of_find_i2c_adapter_by_node() returns NULL and
			 * vc4_hdmi loops on -EPROBE_DEFER.
			 *
			 * Both nodes' pages are already mapped: ddc0's bsc
			 * (0xfef04500) by hdmi0's 0xfef04000 and its auto-i2c
			 * (0xfef00b00) by aon_intr's page; ddc1's bsc
			 * (0xfef09500) by hdmi1's 0xfef09000 and its auto-i2c
			 * (0xfef05b00) by hdmi1's 0xfef05000. Hence no xen,*.
			 */
			ddc0: i2c@fef04500 {
				compatible = "brcm,bcm2711-hdmi-i2c";
				reg = <0x0 0xfef04500 0x0 0x100>,
				      <0x0 0xfef00b00 0x0 0x300>;
				reg-names = "bsc", "auto-i2c";
				clock-frequency = <97500>;
				#address-cells = <1>;
				#size-cells = <0>;
				status = "okay";
			};

			ddc1: i2c@fef09500 {
				compatible = "brcm,bcm2711-hdmi-i2c";
				reg = <0x0 0xfef09500 0x0 0x100>,
				      <0x0 0xfef05b00 0x0 0x300>;
				reg-names = "bsc", "auto-i2c";
				clock-frequency = <97500>;
				#address-cells = <1>;
				#size-cells = <0>;
				status = "okay";
			};

			/*
			 * ---- HVS (display compositor) ----
			 * BCM2711 wires HVS straight to GIC SPI 97 (no L2
			 * controller) and gives it a single unnamed clock;
			 * vc4_hvs.c for VC4_GEN_5 does devm_clk_get(dev, NULL),
			 * so `clock-names` must stay absent to match the host.
			 * reg is 0x8000 = 8 host pages.
			 */
			hvs: hvs@fe400000 {
				compatible = "brcm,bcm2711-hvs";
				reg = <0x0 0xfe400000 0x0 0x8000>;
				interrupts = <0x0 97 0x4>;	/* GIC SPI 97 LEVEL_HIGH */
				interrupt-parent = <&gic>;
				clocks = <&firmware_clocks 4>;
				xen,path = "/soc/hvs@7e400000";
				xen,force-assign-without-iommu;
				xen,reg = <0x0 0xfe400000 0x0 0x8000 0x0 0xfe400000>;
				status = "okay";
			};

			/*
			 * ---- PixelValves (CRTCs) ----
			 * vc4_crtc.c binds HDMI0 to bcm2711_pv2_data and HDMI1
			 * to bcm2711_pv4_data, so the dual-head cockpit needs
			 * exactly pixelvalve2 (0xfe20a000, SPI 101) and
			 * pixelvalve4 (0xfe216000, SPI 110).
			 * pixelvalve0/1/3 drive DSI0/DPI, DSI1/SMI and VEC and
			 * are not claimed here.
			 *
			 * NOTE: pixelvalve1 (/soc/pixelvalve@7e207000) shares
			 * GIC SPI 110 with pixelvalve4, so the host overlay
			 * MUST mark it xen,passthrough even though no domain
			 * drives it. Leaving it with the hardware domain makes
			 * Xen route SPI 110 to Dom0 first (handle_node() has no
			 * `status` check, so status="disabled" does not help),
			 * and this claim then fails with -EBUSY, aborting DomD
			 * construction. See the SPI-110 note in
			 * bcm2711-raspberrypi4-64-xen.dtso.
			 */
			pixelvalve2: pixelvalve@fe20a000 {
				compatible = "brcm,bcm2711-pixelvalve2";
				reg = <0x0 0xfe20a000 0x0 0x100>;
				interrupts = <0x0 101 0x4>;	/* GIC SPI 101 */
				interrupt-parent = <&gic>;
				xen,path = "/soc/pixelvalve@7e20a000";
				xen,force-assign-without-iommu;
				xen,reg = <0x0 0xfe20a000 0x0 0x1000 0x0 0xfe20a000>;
				status = "okay";
			};

			pixelvalve4: pixelvalve@fe216000 {
				compatible = "brcm,bcm2711-pixelvalve4";
				reg = <0x0 0xfe216000 0x0 0x100>;
				interrupts = <0x0 110 0x4>;	/* GIC SPI 110 */
				interrupt-parent = <&gic>;
				xen,path = "/soc/pixelvalve@7e216000";
				xen,force-assign-without-iommu;
				xen,reg = <0x0 0xfe216000 0x0 0x1000 0x0 0xfe216000>;
				status = "okay";
			};

			/*
			 * ---- TXP (transposer / writeback) ----
			 * vc4-kms-v3d-pi4-overlay.dts enables &txp, and the RPi
			 * kernel's vc4_plane_create_additional_planes() walks
			 * the CRTC list for the one with feeds_txp set; with no
			 * TXP CRTC that search leaves txp_crtc uninitialised and
			 * drm_crtc_mask() dereferences it. BCM2711's TXP is the
			 * plain brcm,bcm2835-txp at 0xfe004000 (SPI 75) — the
			 * role BCM2712 splits into mop/moplet.
			 */
			txp: txp@fe004000 {
				compatible = "brcm,bcm2835-txp";
				reg = <0x0 0xfe004000 0x0 0x20>;
				interrupts = <0x0 75 0x4>;	/* GIC SPI 75 */
				interrupt-parent = <&gic>;
				xen,path = "/soc/txp@7e004000";
				xen,force-assign-without-iommu;
				xen,reg = <0x0 0xfe004000 0x0 0x1000 0x0 0xfe004000>;
				status = "okay";
			};

			/*
			 * ---- SoC thermal sensor ----
			 * brcm,bcm2711-avs-monitor is a plain syscon with no
			 * clocks, no power domain, no reset and no interrupt, so
			 * it can be handed over unconditionally. RPi4 has no
			 * standard fan node (unlike the RPi5 active cooler on
			 * RP1 PWM), so the thermal zone below only carries the
			 * critical trip — there is no cooling device to map.
			 */
			avs_monitor: avs-monitor@fd5d2000 {
				compatible = "brcm,bcm2711-avs-monitor",
					     "syscon", "simple-mfd";
				reg = <0x0 0xfd5d2000 0x0 0xf00>;
				xen,path = "/soc/avs-monitor@7d5d2000";
				xen,force-assign-without-iommu;
				xen,reg = <0x0 0xfd5d2000 0x0 0x1000 0x0 0xfd5d2000>;
				status = "okay";

				avs_thermal: thermal {
					compatible = "brcm,bcm2711-thermal";
					#thermal-sensor-cells = <0x0>;
				};
			};

			/*
			 * ---- USB2 (dwc2) ----
			 * On-SoC replacement for RP1's dwc3 controllers. It needs no MSI at
			 * all, which is why it looked like the safe bring-up path.
			 *
			 * *** IMPORTANT ON A Pi 4 MODEL B: this is the USB-C connector,
			 * not the four USB-A ports. *** All four USB-A ports hang off the
			 * VL805 xHCI behind /scb/pcie@7d500000, so dwc2 is NOT a drop-in
			 * fallback for the touch panel: the USB-C port is the power input and
			 * comes up in peripheral mode. Using it as a host port needs a
			 * config.txt change (otg_mode / a dwc2 dr_mode=host overlay -- confirm
			 * the exact knob against the Raspberry Pi config.txt documentation)
			 * AND powering the board from the GPIO 5 V pins so the connector is
			 * free. The realistic fallback is therefore a powered USB-C hub, not
			 * "use USB2 instead".
			 *
			 * The second reg block (0xfe00b200) lives in the
			 * mailbox's 0xfe00b000 page, so only the 64 KiB main
			 * block is mapped here. Both host IRQs are GIC SPIs
			 * (73 "usb", 40 "soft") and are routed via xen,path.
			 */
			usb: usb@fe980000 {
				compatible = "brcm,bcm2708-usb";
				reg = <0x0 0xfe980000 0x0 0x10000>,
				      <0x0 0xfe00b200 0x0 0x200>;
				interrupts = <0x0 73 0x4>,
					     <0x0 40 0x4>;
				interrupt-names = "usb", "soft";
				interrupt-parent = <&gic>;
				#address-cells = <0x1>;
				#size-cells = <0x0>;
				clocks = <&clk_usb>;
				clock-names = "otg";
				power-domains = <&power 6>;	/* RPI_POWER_DOMAIN_USB */
				xen,path = "/soc/usb@7e980000";
				xen,force-assign-without-iommu;
				xen,reg = <0x0 0xfe980000 0x0 0x10000 0x0 0xfe980000>;
				status = "okay";
			};

			/*
			 * pl011 -> the on-board CYW43455 Bluetooth.
			 *
			 * Xen's console is the mini UART (boot.cmd passes
			 * dtuart=/soc/serial@7e215040) and config.txt carries no
			 * dtoverlay, so the stock wiring holds: pl011 on GPIO30-33
			 * talking to the BT module at 3 Mbaud. That baud is the whole
			 * point — 8N1 gives baud/10 bytes per second, so 3 Mbaud
			 * carries 2400 kbps of HCI payload against A2DP SBC's
			 * 229-328 kbps, while the mini UART's 230400 would give only
			 * 184 kbps.
			 *
			 * The Xen host overlay marks &uart0 xen,passthrough so Xen
			 * releases SPI 121; see the long note there for why the marker
			 * cannot be skipped (Xen only probes the dtuart= node, so
			 * pl011 is never used_by DOMID_XEN).
			 *
			 * compatible: keep ALL THREE, exactly as the host DT has them.
			 * drivers/of/platform.c:361-366 creates an AMBA device for any
			 * node compatible with "arm,primecell", so this binds to
			 * amba-pl011.c's AMBA pl011_probe with vendor_arm — the same
			 * path a stock Pi takes. Reducing it to "arm,pl011-axi" alone
			 * would instead hit pl011_axi_probe() (amba-pl011.c:3104) with
			 * vendor_arm_axi, i.e. a different register access width and
			 * different vendor data. The AMBA path is also why apb_pclk has
			 * to exist: amba_device_add() does clk_get(dev, "apb_pclk")
			 * before probe.
			 *
			 * reg is rounded up from the host's 0x200 to a full 4 KiB page
			 * because Xen maps MMIO per page — the same idiom the Xen host
			 * overlay uses for &uart0. That page also holds uart2..uart5,
			 * which both boot scripts remove so this node is its single
			 * owner.
			 *
			 * No pinctrl: the host points at <&uart0_pins &bt_pins> under
			 * gpio@7e200000 and DomD has no GPIO controller. boot.cmd muxes
			 * GPIO30-33 to ALT3 with a raw GPFSEL3 write before Xen starts.
			 * Same reasoning as sdio_pins/audio_pins elsewhere in this file.
			 */
			uart0: serial@fe201000 {
				compatible = "arm,pl011-axi", "arm,pl011", "arm,primecell";
				reg = <0x0 0xfe201000 0x0 0x1000>;
				interrupts = <0x0 121 0x4>;	/* GIC SPI 121 */
				interrupt-parent = <&gic>;
				clocks = <&clk_uart>, <&clk_apb>;
				clock-names = "uartclk", "apb_pclk";
				arm,primecell-periphid = <0x341011>;
				cts-event-workaround;
				uart-has-rtscts;
				/*
				 * skip-init is INERT in this kernel and is present only
				 * to keep this node identical to the host's. Measured:
				 * nothing under drivers/ or arch/arm64/ consumes it, and
				 * amba-pl011.c does not read it — so Linux DOES fully
				 * initialise this port, which is what hci_bcm needs in
				 * order to set the baud via
				 * serdev_device_set_baudrate(). Do not read this line as
				 * "the firmware already set the UART up, so the clock
				 * must be fine".
				 */
				skip-init;
				xen,path = "/soc/serial@7e201000";
				xen,force-assign-without-iommu;
				xen,reg = <0x0 0xfe201000 0x0 0x1000 0x0 0xfe201000>;
				status = "okay";

				/*
				 * hci_uart binds here over serdev; hci_bcm picks the
				 * node up via brcm,bcm43438-bt with
				 * bcm43438_device_data (hci_bcm.c
				 * bcm_bluetooth_of_match) and downloads
				 * brcm/BCM4345C0.hcd — btbcm_initialize() always also
				 * tries the board-name-less filename, which is what
				 * bluez-firmware-rpidistro-bcm4345c0-hcd installs, so
				 * the guest DT having no root compatible does not
				 * matter here (unlike brcmfmac, which needed
				 * brcm,board-type).
				 *
				 * max-speed drives the post-patchram baud switch
				 * (hci_bcm.c:1232 reads it into oper_speed). Measured on
				 * the board: 3000000, and the controller then answers
				 * with chip id 107, BCM4345C0 build 0382.
				 *
				 * shutdown-gpios = BT_ON, expgpio line 0. The firmware
				 * GPIO provider is already in this partial DT (see the
				 * `firmware` node), so it resolves inside DomD.
				 *
				 * brcm,bt-pcm-int-params routes SCO over the HCI
				 * transport instead of the chip's PCM pins, which is
				 * what HFP needs in a guest that has no PCM/I2S wiring
				 * at all. hci_bcm.c:628-635 sends it during bcm_setup()
				 * via btbcm_write_pcm_int_params() (HCI opcode 0xfc1c,
				 * btbcm.c:199-215); the default pcm_int_params[0] = 0xff
				 * means "leave alone" (hci_bcm.c:1259, :1527). Byte 0 is
				 * sco-routing: 0 = PCM, 1 = Transport, 2 = Codec,
				 * 3 = I2S — see
				 * Documentation/devicetree/bindings/net/bluetooth/brcm,bluetooth.yaml:93-103.
				 * The remaining four bytes match both in-tree users,
				 * arch/arm/boot/dts/rockchip/rk3288-veyron-broadcom-bluetooth.dtsi:20
				 * and arch/arm64/boot/dts/nvidia/tegra210-smaug.dts:1356.
				 * Harmless for A2DP, required for HFP.
				 *
				 * vbat-supply / vddio-supply are NOT optional in a
				 * dom0less guest, and this is the one difference from a
				 * stock Raspberry Pi DT, which declares neither.
				 * hci_bcm.c's bcm_get_resources() takes both with
				 * devm_regulator_get() (not the _optional variant). On a
				 * stock Pi the regulator core inserts dummy supplies and
				 * that succeeds; here it refuses:
				 *   include/linux/of.h:1717-1720 — of_have_populated_dt()
				 *     tests only whether the DT ROOT has a `compatible`;
				 *   drivers/regulator/core.c:6585-6586 —
				 *     has_full_constraints is set from that and nothing
				 *     else, and dummy supplies need it.
				 * A dom0less guest DT root carries only #address-cells /
				 * #size-cells, so has_full_constraints stays false, dummy
				 * supplies are refused and probe fails with
				 * "error -ENODEV: Failed to get supply 'vbat'" — hci0
				 * never appears. The number of regulators in the tree is
				 * irrelevant. Hence the explicit always-on
				 * bt_vbat_reg below.
				 */
				bluetooth {
					compatible = "brcm,bcm43438-bt";
					max-speed = <3000000>;
					shutdown-gpios = <&expgpio 0 0>;	/* BT_ON */
					fallback-bd-address;
					brcm,bt-pcm-int-params = [01 02 00 01 01];
					vbat-supply = <&bt_vbat_reg>;
					vddio-supply = <&bt_vbat_reg>;
					status = "okay";
				};
			};
		};

		/*
		 * clk_usb: the host declares it at root level as
		 * /clocks/clk-usb (480 MHz). dwc2 only needs the handle to
		 * resolve, the real gating is firmware-side.
		 */
		clk_usb: clk-usb {
			compatible = "fixed-clock";
			#clock-cells = <0>;
			clock-frequency = <480000000>;
			clock-output-names = "otg";
		};

		/*
		 * pl011's two clocks. The host uses <&clocks BCM2835_CLOCK_UART>
		 * (cprman index 19) and <&clocks BCM2835_CLOCK_VPU> (index 20), and
		 * cprman is not passed through — same situation as emmc2 and mmcnr,
		 * and the same fixed-clock substitute.
		 *
		 * 48 MHz is init_uart_clock's default, i.e. what the firmware
		 * programs into CM_UARTDIV. THE VALUE MATTERS: amba-pl011 computes
		 * the baud divisor from clk_get_rate(), so if the real rate is not
		 * 48 MHz the link runs at the wrong baud by exactly that ratio and
		 * the BT firmware download fails. A fixed-clock cannot open a gate
		 * either. Both hold on the board: the controller answers (chip id
		 * 107, BCM4345C0 build 0382), which it cannot do over a link whose
		 * baud comes from a wrong rate or whose clock is gated.
		 *
		 * apb_pclk is only there because amba_device_add() insists on it;
		 * amba-pl011 never reads its rate.
		 */
		clk_uart: clk-uart {
			compatible = "fixed-clock";
			#clock-cells = <0>;
			clock-frequency = <48000000>;
			clock-output-names = "uart-clock";
		};

		clk_apb: clk-apb {
			compatible = "fixed-clock";
			#clock-cells = <0>;
			clock-frequency = <48000000>;
			clock-output-names = "apb-pclk";
		};

		/* ==============================================================
		 * v3d_bus — identity DMA (V3D has its own MMU and /v3dbus
		 * declares dma-ranges over the full 16 GiB).
		 * ============================================================== */
		v3d_bus: v3d-bus {
			compatible = "simple-bus";
			#address-cells = <0x2>;
			#size-cells = <0x2>;
			ranges;
			dma-ranges = <0x0 0x0 0x0 0x0 0x4 0x0>;

			/*
			 * BCM2711 V3D 4.2: only TWO reg blocks (hub + core0),
			 * no "sms" block — that is a BCM2712/V3D-7.1 addition.
			 * Single unnamed clock (devm_clk_get_optional(dev, NULL)).
			 * power-domains/resets point at bcm2835-pm exactly as in
			 * the host DT, which is why `pm` is passed through above.
			 */
			/* Node name follows reg[0] (hub) to keep dtc's
			 * simple_bus_reg check quiet; the HOST node is
			 * /v3dbus/v3d@7ec04000 and that is what xen,path
			 * must say. */
			v3d: v3d@fec00000 {
				compatible = "brcm,2711-v3d";
				reg = <0x0 0xfec00000 0x0 0x4000>,
				      <0x0 0xfec04000 0x0 0x4000>;
				reg-names = "hub", "core0";
				clocks = <&firmware_clocks 5>;
				power-domains = <&pm 1>;	/* BCM2835_POWER_DOMAIN_GRAFX_V3D */
				resets = <&pm 0>;		/* BCM2835_RESET_V3D */
				interrupts = <0x0 74 0x4>;	/* GIC SPI 74 */
				interrupt-parent = <&gic>;
				xen,path = "/v3dbus/v3d@7ec04000";
				xen,force-assign-without-iommu;
				xen,reg = <0x0 0xfec00000 0x0 0x4000 0x0 0xfec00000>,
					  <0x0 0xfec04000 0x0 0x4000 0x0 0xfec04000>;
				status = "okay";
			};
		};

		/* ==============================================================
		 * scb_bus — the host /scb dma-ranges verbatim: the VideoCore
		 * peripheral alias window, then identity DMA over 16 GiB.
		 * Hosts the PCIe root complex (VL805 USB3), GENET and dma40.
		 *
		 * CORRECTED(2026-07-26): this used to declare 3 GiB
		 * (size 0xc0000000) while claiming to match the host — the host
		 * /scb actually declares an identity window of 16 GiB:
		 *   /scb dma-ranges = <0x04 0x7c000000 0x00 0xfc000000 0x00 0x3800000
		 *                      0x00 0x00       0x00 0x00       0x04 0x00>;
		 *                                                      ^^^^^^^^^ 16 GiB
		 * and the GENET comment below asserted the 16 GiB figure too, so the
		 * file contradicted itself in three places. The 3 GiB value was not
		 * functionally wrong — every DomD static-mem bank (0x08000000,
		 * 0x40000000, 0x80000000) is below 0xc0000000 — but it made the
		 * surrounding prose false and would have bitten a later bank layout.
		 * of_dma_get_max_cpu_address() takes the MINIMUM across buses, so
		 * widening this does not disturb the low-CMA placement that soc_bus
		 * pins (see the header note); it only stops this bus from being the
		 * one that limits it.
		 * ============================================================== */
		scb_bus: scb-bus {
			compatible = "simple-bus";
			#address-cells = <0x2>;
			#size-cells = <0x2>;
			ranges;
			/*
			 * THE PERIPHERAL WINDOW IS WHAT MAKES HDMI AUDIO AUDIBLE.
			 * vc4_hdmi's MAI FIFO is a SLAVE register, not a buffer:
			 *   vc4_hdmi.c:2277-2286
			 *     index = of_property_match_string(..., "reg-names", "hd");
			 *     iomem = platform_get_resource(pdev, IORESOURCE_MEM, index);
			 *     vc4_hdmi->audio.dma_data.addr = iomem->start + mai_data->offset;
			 *   = 0xfef20000 (hd, see hdmi0) + 0x1c (HDMI_MAI_DATA,
			 *     vc4_hdmi_regs.h:250) = 0xfef2001c.  hdmi1 uses +0x3c (:343).
			 * bcm2835-dma.c:1032 maps that against dma40's own device, i.e.
			 * against THIS bus:
			 *     dst = dma_map_resource(chan->device->dev, c->cfg.dst_addr, ...)
			 * and the translation walks dma_range_map and returns the FIRST
			 * match. With only the memory entry, 0xfef2001c falls inside the
			 * 16 GiB identity window and comes back unchanged instead of
			 * becoming the VC peripheral alias 0x4_7ef2001c. Nothing reports an
			 * error: the controller writes audio frames to an address that is
			 * not the FIFO, hw_ptr never advances, and there is no xrun and no
			 * dmesg line to find.
			 *
			 * WHY THE ALIAS HOLDS UNDER XEN. (1) 0xfef20000 is the same inside
			 * DomD as on the host -- hdmi0's xen,reg maps
			 * <0x0 0xfef20000 0x0 0x1000 0x0 0xfef20000>, host_pbase ==
			 * guest_gbase -- so the value this window translates is the real
			 * register address. (2) 0x4_7ef2001c is a bus-master access by dma40
			 * to a PERIPHERAL alias, not to guest RAM. BCM2711 has no IOMMU
			 * (every assignment here uses xen,force-assign-without-iommu and
			 * dma40 declares no `iommus`), so Xen does not interpose on device
			 * DMA and the SoC fabric decodes the alias exactly as for host Linux.
			 *
			 * ORDER IS LOAD-BEARING: the 16 GiB memory entry would SHADOW a
			 * peripheral entry placed after it. Upstream has the same order
			 * (arch/arm/boot/dts/broadcom/bcm2711-rpi-ds.dtsi:123-124).
			 * RAM never lies in 0xfc000000-0xff7fffff, so PCIe, GENET and every
			 * DMA buffer still take the identity entry, and this bus's maximum
			 * CPU address is unchanged (the low-CMA placement soc_bus pins is
			 * not disturbed).
			 *
			 * v3d_bus keeps the memory-only form: V3D has its own MMU and
			 * upstream /v3dbus declares the identity window only.
			 *
			 * Verified on hardware 2026-09-23 (Xen 4.22, DomD with dma40): a 440 Hz
			 * tone played in DomA reached the panel through vc4hdmi0. Before
			 * that the window had had no hardware check, and HDMI audio had never
			 * been audible on the Pi 4.
			 */
			dma-ranges = <0x4 0x7c000000 0x0 0xfc000000 0x0 0x03800000>,
				     <0x0 0x0        0x0 0x0        0x4 0x0>;

			/*
			 * ---- 40-bit DMA controller (dma40) ----
			 * Two DomA features need it:
			 *  - HDMI audio: both HDMI nodes point their audio-rx DREQ here.
			 *  - hardware H.264 decode: vchiq_arm.c:219 looks the controller
			 *    up by compatible ("brcm,bcm2711-dma") and FAILS ITS PROBE
			 *    without it (measured 2026-09-23 on this board:
			 *      bcm2835_vchiq fe00b840.mailbox: 40-bit DMA controller not found
			 *      probe with driver bcm2835_vchiq failed with error -22
			 *    ), so bcm2835-codec never appears as /dev/video10, qemu's
			 *    virtio-media cannot open it, and xl create of DomA fails as a
			 *    whole.
			 *
			 * The host has TWO DMA controllers and DomD takes both, for
			 * different users:
			 *   /soc/dma@7e007000   brcm,bcm2835-dma   mask 0x7f5  Wi-Fi SDIO
			 *                       (legacy_dma_bus below)
			 *   /scb/dma@7e007b00   brcm,bcm2711-dma   mask 0x7000 this node
			 *
			 * `#dma-cells = <1>` is a DREQ number, not a channel index
			 * (Documentation/devicetree/bindings/dma/brcm,bcm2835-dma.yaml),
			 * so DREQ 10 (HDMI0) and 17 (HDMI1) are served out of the channel
			 * pool that brcm,dma-channel-mask names -- 0x7000 = channels
			 * 12/13/14. Keep the mask at the host value: narrowing it would
			 * starve the pool, widening it would claim the legacy engine's
			 * channels.
			 *
			 * xen,reg is page-aligned down to 0xfe007000 because the register
			 * block starts at +0xb00 inside that page. The legacy engine
			 * declares the same page: the second deliberate duplicate in this
			 * file (see the header rules).
			 *
			 * The four IRQs are the host node's (GIC SPI 89-92, "dma11".."dma14");
			 * the IRQs of the node named by xen,path are what Xen routes, and the
			 * Xen host overlay marks /scb/dma@7e007b00 xen,passthrough so they are
			 * not given to the hardware domain first.
			 *
			 * WHY scb_bus AND NOT soc_bus: the audio buffer is allocated and
			 * DMA-mapped against the DMA CONTROLLER's struct device, not the HDMI
			 * card's (sound/soc/soc-generic-dmaengine-pcm.c: dmaengine_dma_dev()
			 * at :28, snd_pcm_set_managed_buffer() at :259). scb_bus reaches the
			 * full 16 GiB, so every DomD static-mem bank is inside it; soc_bus
			 * would clamp it to the VideoCore alias window, and with no IOMMU a
			 * buffer above that window transfers garbage rather than failing.
			 * It also matches the host DT, where this controller is under /scb.
			 *
			 * OUTSIDE THE SD-STRIP BLOCK ON PURPOSE: both Dom0 flavours give HDMI
			 * to DomD, so both need the controller.
			 */
			dma40: dma@fe007b00 {
				compatible = "brcm,bcm2711-dma";
				reg = <0x0 0xfe007b00 0x0 0x400>;
				interrupts = <0x0 89 0x4>,
					     <0x0 90 0x4>,
					     <0x0 91 0x4>,
					     <0x0 92 0x4>;
				interrupt-names = "dma11", "dma12",
						  "dma13", "dma14";
				interrupt-parent = <&gic>;
				#dma-cells = <0x1>;
				brcm,dma-channel-mask = <0x7000>;
				xen,path = "/scb/dma@7e007b00";
				xen,force-assign-without-iommu;
				xen,reg = <0x0 0xfe007000 0x0 0x1000 0x0 0xfe007000>;
				status = "okay";
			};

			/*
			 * ---- BCM2711 PCIe RC + VL805 xHCI (USB3) ----
			 * This is the RPi4 answer to "where did RP1's USB go",
			 * and it is structurally MUCH simpler than the RPi5
			 * pcie2+mip0 pair:
			 *   - the MSI controller is INSIDE the RC
			 *     (msi-controller + msi-parent = <&pcie0>), raising
			 *     GIC SPI 148; there is no separate MIP to pass
			 *     through and no msi-ranges quirk, so the RPi5
			 *     `4.22-0002-route-msi-ranges` patch has no RPi4
			 *     counterpart and was dropped from the bbappend.
			 *   - the MSI doorbell is a PCI bus address captured by
			 *     the RC's internal MSI BAR; the write never reaches
			 *     DRAM, it just sets a bit in MSI_INT_STATUS and
			 *     raises SPI 148. With dma-ranges size 0xc0000000
			 *     pcie-brcmstb rounds rc_bar2_size up to 4 GiB with
			 *     offset 0, so BOTH LT_4GB conditions are false and
			 *     it selects BRCM_MSI_TARGET_ADDR_GT_4GB
			 *     (0xf_fffffffc) — a 64-bit MSI address. Either way
			 *     nothing needs a p2m mapping: the guest only needs
			 *     (a) the RC MMIO, (b) SPI 148, (c) write access to
			 *     VL805's config space (which goes through the RC's
			 *     index/data window at 0x9000/0x8000, not ECAM).
			 *   - BCM2711's RC needs no `resets` and no `clocks`
			 *     (the host node has neither), unlike BCM2712 which
			 *     needs rescal + bridge.
			 *
			 * The 32-bit outbound window is trimmed from the host's
			 * 1 GiB (bus 0xc0000000 -> host 0x6_00000000) to 4 MiB
			 * so the guest PCI core can only place VL805's BARs
			 * inside the region actually covered by xen,reg. Xen/ARM
			 * has no vPCI emulation, so the guest programs the real
			 * BARs and any unmapped placement faults.
			 *
			 * REMAINS UNPROVEN ON HARDWARE (see README.md "Known limitations"). If MSI
			 * misbehaves, keep the USB2 dwc2 path above and either
			 * drop this node or add `brcm,enable-l1ss`-style quirks.
			 */
			/*
			 * ---- Gigabit Ethernet (GENET v5) ----
			 * The RPi4 replacement for RP1's `cdns,macb` NIC. As on
			 * RPi5, the NIC belongs to DomD in BOTH Dom0 flavours:
			 * DomD runs the flat L2 bridge (xenbr0) and Dom0 reaches
			 * the network through the Dom0<->DomD vif, so the Zephyr
			 * Dom0 needs no network stack at all. The only
			 * meta-xt-common change this forces is the NIC name pin,
			 * which now matches the bcmgenet driver instead of macb
			 * (xen-network/files/00-genet-eth0.link).
			 *
			 * GENET is not DMA-limited: the host /scb dma-ranges reach
			 * 16 GiB and scb_bus above mirrors that, so it can use
			 * DomD's high banks freely — which is why it sits on
			 * scb_bus and not soc_bus.
			 */
			genet: ethernet@fd580000 {
				compatible = "brcm,bcm2711-genet-v5";
				reg = <0x0 0xfd580000 0x0 0x10000>;
				#address-cells = <0x1>;
				#size-cells = <0x1>;
				interrupts = <0x0 157 0x4>,
					     <0x0 158 0x4>;
				interrupt-parent = <&gic>;
				phy-mode = "rgmii-rxid";
				phy-handle = <&phy1>;
				/*
				 * A locally-administered, DETERMINISTIC MAC.
				 *
				 * This used to be [00 00 00 00 00 00], carried over
				 * from the rpi5 file. All-zero is not a valid
				 * Ethernet address, so of_get_mac_address() rejects
				 * it (is_valid_ether_addr() fails), the nvmem lookup
				 * finds nothing either, and bcmgenet_probe() ends up
				 * at drivers/net/ethernet/broadcom/genet/bcmgenet.c:
				 *   dev_warn(&pdev->dev, "using random Ethernet MAC\n");
				 *   eth_hw_addr_random(dev);
				 * i.e. DomD's eth0 gets a DIFFERENT MAC on every boot.
				 *
				 * The board's real MAC cannot be injected here. The
				 * firmware patches it into the HOST device tree, and
				 * DomD never sees that tree — it gets this partial DT.
				 * U-Boot does know it (board/raspberrypi/rpi/rpi.c
				 * set_usbethaddr() queries GET_MAC_ADDRESS over the
				 * VideoCore mailbox and sets $ethaddr), but $ethaddr is
				 * a colon-separated string and `fdt set` needs a byte
				 * array `[xx xx ..]`; Hush cannot convert one to the
				 * other, and the DomD DTB is a second blob that would
				 * have to be swapped in with `fdt addr` mid-script.
				 *
				 * So: a fixed value with the locally-administered bit
				 * set (0x02) and no OUI, spelling "DOMD" in the low
				 * bytes. Deterministic ARP/lease behaviour, and clearly
				 * not a vendor address.
				 *
				 * CAVEAT: it is fixed, so two of these boards on ONE L2
				 * segment would collide. Change the last octet per board
				 * if that ever happens.
				 */
				local-mac-address = [02 44 4f 4d 44 01];
				xen,path = "/scb/ethernet@7d580000";
				xen,force-assign-without-iommu;
				xen,reg = <0x0 0xfd580000 0x0 0x10000 0x0 0xfd580000>;
				status = "okay";

				genet_mdio: mdio@e14 {
					compatible = "brcm,genet-mdio-v5";
					reg = <0xe14 0x8>;
					reg-names = "mdio";
					#address-cells = <0x1>;
					#size-cells = <0x0>;

					phy1: ethernet-phy@1 {
						reg = <0x1>;
						brcm,powerdown-enable;
						led-modes = <0x0 0x8>;
					};
				};
			};

			pcie0: pcie@fd500000 {
				compatible = "brcm,bcm2711-pcie";
				reg = <0x0 0xfd500000 0x0 0x9310>;
				device_type = "pci";
				#address-cells = <0x3>;
				#size-cells = <0x2>;
				#interrupt-cells = <0x1>;
				linux,pci-domain = <0>;
				interrupt-parent = <&gic>;
				interrupts = <0x0 147 0x4>,	/* pcie */
					     <0x0 148 0x4>;	/* msi  */
				interrupt-names = "pcie", "msi";
				/*
				 * Legacy INTx map, copied from the host RC. NOTE: Xen
				 * does NOT route these four SPIs to DomD, and cannot
				 * be made to from here.
				 * map_device_irqs_to_domain() (xen/arch/arm/device.c)
				 * iterates dt_number_of_irq(dev), i.e. the node's own
				 * `interrupts` property — 147/148 — and never walks
				 * `interrupt-map`. The host RC declares exactly the same
				 * two (`interrupts = <0 0x93 4>, <0 0x94 4>`) and no
				 * host node anywhere claims 143..146 in an `interrupts`
				 * property, so those vIRQs simply do not exist in any
				 * domain.
				 * Consequence: if MSI ever fails and Linux falls back to
				 * legacy INTx, DomD gets a silently interrupt-less
				 * device. That is acceptable here only because BCM2711
				 * puts the MSI controller INSIDE the RC
				 * (msi-parent = <&pcie0>, SPI 148, which IS routed), so
				 * the MSI path needs no vPCI support from Xen. The map is
				 * kept so the DT is well-formed for child enumeration and
				 * so the numbers are recorded; do not read it as a
				 * working fallback. See README.md "Known limitations".
				 */
				interrupt-map-mask = <0x0 0x0 0x0 0x7>;
				interrupt-map = <0x0 0x0 0x0 0x1 &gic 0x0 143 0x4>,
						<0x0 0x0 0x0 0x2 &gic 0x0 144 0x4>,
						<0x0 0x0 0x0 0x3 &gic 0x0 145 0x4>,
						<0x0 0x0 0x0 0x4 &gic 0x0 146 0x4>;
				msi-controller;
				msi-parent = <&pcie0>;
				brcm,enable-ssc;
				ranges = <0x02000000 0x0 0xc0000000
					  0x6 0x00000000 0x0 0x00400000>;
				dma-ranges = <0x02000000 0x0 0x00000000
					      0x0 0x00000000 0x0 0xc0000000>;
				xen,path = "/scb/pcie@7d500000";
				xen,force-assign-without-iommu;
				xen,reg = <0x0 0xfd500000 0x0 0xa000 0x0 0xfd500000>,
					  <0x6 0x00000000 0x0 0x00400000 0x6 0x00000000>;
				status = "okay";

				pci@0,0 {
					device_type = "pci";
					#address-cells = <0x3>;
					#size-cells = <0x2>;
					ranges;
					reg = <0x0 0x0 0x0 0x0 0x0>;

					/*
					 * VL805. `resets` makes xhci_pci ask
					 * the VideoCore to reload the VL805 SPI
					 * firmware before enumeration —
					 * mandatory on RPi4 boards whose EEPROM
					 * is not pre-flashed.
					 */
					usb@0,0 {
						reg = <0x0 0x0 0x0 0x0 0x0>;
						resets = <&reset 0>;	/* RASPBERRYPI_FIRMWARE_RESET_ID_USB */
					};
				};
			};
		};

		/* ==============================================================
		 * vc4 aggregate.
		 *
		 * On BCM2711 the host /gpu node is a LEAF (no children) —
		 * vc4_drv.c's vc4_match_add_drivers() collects components with
		 * platform_find_device_by_driver() over the whole system, not by
		 * walking children, so the BCM2712-style "put HVS/V3D/HDMI under
		 * gpu" arrangement is unnecessary here and this mirrors the host
		 * DT instead. `raspberrypi,firmware` is what the host node
		 * carries and vc5 needs it to query the firmware.
		 * ============================================================== */
		vc4: gpu {
			compatible = "brcm,bcm2711-vc5";
			raspberrypi,firmware = <&firmware>;
			status = "okay";
		};

		/*
		 * Thermal zone. dom0less copies only /passthrough, and 6.18's
		 * thermal_of finds the zones with of_find_node_by_name(NULL,
		 * "thermal-zones"), so placing them here works. Coefficients are
		 * the BCM2711 values from the host DT (<(-487) 410040>), not the
		 * BCM2712 ones. No cooling-maps: RPi4 has no standard fan.
		 */
		thermal-zones {
			cpu_thermal: cpu-thermal {
				polling-delay-passive = <0>;
				polling-delay = <1000>;
				coefficients = <0xfffffe19 0x641b8>;
				thermal-sensors = <&avs_thermal>;

				trips {
					cpu_crit: cpu-crit {
						temperature = <110000>;
						hysteresis = <0>;
						type = "critical";
					};
				};

				cooling-maps {
				};
			};
		};

		/*
		 * Bluetooth vbat / vddio. A fixed regulator with NO gpio, so it
		 * switches nothing — the CYW43455 is powered from the board
		 * unconditionally. It exists solely to satisfy hci_bcm.c's
		 * devm_regulator_get() calls, which cannot fall back to dummy
		 * supplies in a dom0less guest; the mechanism is spelled out at the
		 * `bluetooth` node above.
		 *
		 * It MUST stay OUTSIDE the SD-STRIP block below. The references to it
		 * are in the `bluetooth` node, which is outside the block, so a
		 * definition inside it would be deleted by domd-vc4.bb's sed for
		 * DOM0_OS=linux and dtc would then reject the whole tree:
		 *     ERROR (phandle_references):
		 *         /passthrough/soc-bus/serial@fe201000/bluetooth:
		 *         Reference to non-existent node or label "bt_vbat_reg"
		 * — no DTB at all, and only for that one flavour. Same hazard the
		 * /aliases mmc entries are marked for.
		 *
		 * sd_vcc_reg must NOT be reused: it carries SD_PWR_ON (expgpio 6), so
		 * a Bluetooth probe would end up switching the SD card's power.
		 */
		bt_vbat_reg: bt-vbat-reg {
			compatible = "regulator-fixed";
			regulator-name = "bt-vbat";
			regulator-min-microvolt = <3300000>;
			regulator-max-microvolt = <3300000>;
			regulator-always-on;
			status = "okay";
		};

		/* SODEV-LINUX-DOM0-SD-STRIP-BEGIN: domd-vc4.bb removes this whole
		 * block for DOM0_OS=linux. In the linux flavour the thin Linux Dom0
		 * is the hardware domain and KEEPS emmc2 (it owns /dev/mmcblk0), so
		 * DomD must not re-request GIC SPI 126 (route_irq_to_guest -EBUSY).
		 * In the Zephyr flavour Dom0 has no block stack at all, so DomD owns
		 * the SD directly and serves p3/p4 to DomU/DomA as virtio-blk.
		 * dtc drops comments, so the zephyr DTB is byte-identical with these
		 * markers present.
		 * ------------------------------------------------------------------
		 * emmc2_bus mirrors the host /emmc2bus wrapper, but NOT its dma-ranges
		 * as they appear in the shipped bcm2711-rpi-4-b.dtb. The RPi4 firmware
		 * REWRITES that property before handing the DT to the bootloader:
		 *
		 *   bcm2711-rpi-4-b.dtb (file)   dma-ranges = <0x0 0xc0000000 0x0 0x0 0x40000000>
		 *   running DT (after fixup)     dma-ranges = <0x0 0x0        0x0 0x0 0xfc000000>
		 *
		 * i.e. emmc2 addresses RAM DIRECTLY, identity-mapped over the whole
		 * usable 3.94 GiB -- it is NOT behind the low-1 GiB VideoCore alias that
		 * /soc (mailbox, VPU) still uses. Read back from the live tree with
		 * `fdt print /emmc2bus` at the U-Boot prompt.
		 *
		 * Carrying the file's pre-fixup alias here made DomD add 0xc0000000 to
		 * every SD DMA address, so the controller read and wrote at addresses
		 * that were not the buffers Linux had prepared. The data came back
		 * corrupted, which surfaced as (hardware, 2026-08-05 and 2026-08-18,
		 * two cards from different vendors):
		 *   ADMA:  mmc0: ADMA error: 0x02000000 -> error -5, retried forever
		 *          mmc0: unrecognised SCR structure version 4   (garbage SCR)
		 *   SDMA:  mmc0: invalid bus width -> error -22          (garbage SCR)
		 *   PIO:   works (no bus-master DMA at all)
		 * and was very nearly written off as a media-specific quirk needing a
		 * PIO fallback. With the identity mapping below the card comes up at
		 * full DDR50 with ADMA and zero errors, no quirk needed.
		 * ------------------------------------------------------------------ */
		emmc2_bus: emmc2-bus {
			compatible = "simple-bus";
			#address-cells = <0x2>;
			#size-cells = <0x2>;
			ranges;
			dma-ranges = <0x0 0x0 0x0 0x0 0x0 0xfc000000>;

			emmc2: mmc@fe340000 {
				compatible = "brcm,bcm2711-emmc2";
				reg = <0x0 0xfe340000 0x0 0x100>;
				interrupts = <0x0 126 0x4>;	/* GIC SPI 126 */
				interrupt-parent = <&gic>;
				clocks = <&clk_emmc2>;
				vqmmc-supply = <&sd_io_1v8_reg>;
				vmmc-supply = <&sd_vcc_reg>;
				broken-cd;
				mmc-ddr-3_3v;
				bus-width = <0x4>;
				xen,path = "/emmc2bus/mmc@7e340000";
				xen,force-assign-without-iommu;
				xen,reg = <0x0 0xfe340000 0x0 0x1000 0x0 0xfe340000>;
				status = "okay";
			};
		};

		/*
		 * emmc2's clock is <&clocks BCM2711_CLOCK_EMMC2> (cprman index
		 * 0x33) on the host. Substitute a fixed clock rather than pull
		 * cprman into DomD.
		 *
		 * 100 MHz is the Raspberry Pi firmware's DEFAULT emmc2 rate on
		 * BCM2711, not a value that can be derived from this tree: the
		 * cprman entry for it (drivers/clk/bcm/clk-bcm2835.c,
		 * BCM2711_CLOCK_EMMC2 = REGISTER_PER_CLK(...)) only describes the
		 * CM_EMMC2CTL/CM_EMMC2DIV registers — the actual rate is whatever
		 * the firmware programmed, and config.txt `dtparam=sd_overclock`
		 * changes it. Treat this number as CONFIGURATION, not fact.
		 *
		 * Why it matters: sdhci-iproc takes this as the base clock and
		 * derives the SD clock divider from it. Declare it too high and
		 * the card is actually clocked slower than intended; too low and
		 * the controller is driven past the negotiated timing, which shows
		 * up as CRC errors under load rather than as a clean failure.
		 * CONFIRM on first boot from DomD:
		 *     dmesg | grep -i 'mmc0:.*SDHCI controller'
		 * (it prints the base clock it computed) and adjust if it differs.
		 * Only the zephyr flavour is affected — in the linux flavour the SD
		 * stays with Dom0, which uses the real cprman clock.
		 */
		clk_emmc2: clk-emmc2 {
			compatible = "fixed-clock";
			#clock-cells = <0x0>;
			clock-output-names = "emmc2-clock";
			clock-frequency = <100000000>;
		};

		/*
		 * SD regulators, copied from the host root-level nodes. Both are
		 * driven by expgpio (firmware GPIO), which is why the firmware
		 * node above exports it.
		 */
		sd_io_1v8_reg: sd-io-1v8-reg {
			compatible = "regulator-gpio";
			regulator-name = "vdd-sd-io";
			regulator-min-microvolt = <1800000>;
			regulator-max-microvolt = <3300000>;
			regulator-boot-on;
			regulator-always-on;
			regulator-settling-time-us = <5000>;
			gpios = <&expgpio 4 0>;
			states = <1800000 0x1>, <3300000 0x0>;
			status = "okay";
		};

		sd_vcc_reg: sd-vcc-reg {
			compatible = "regulator-fixed";
			regulator-name = "vcc-sd";
			regulator-min-microvolt = <3300000>;
			regulator-max-microvolt = <3300000>;
			regulator-boot-on;
			enable-active-high;
			gpios = <&expgpio 6 0>;
			status = "okay";
		};

		/* ==================================================================
		 * Legacy DMA engine (bcm2835-dma) -> DomD, for the Wi-Fi SDIO.
		 * ==================================================================
		 * mmcnr's only route to DMA is this EXTERNAL engine: the Arasan SDHCI
		 * block it sits on has no usable internal bus master (see the
		 * compatible note on mmcnr below). The host wires it up as
		 *     dmas = <&dma-controller@7e007000 11>   / * DREQ 11 * /
		 * so the engine has to be in this domain for bcm2835-mmc.c to get a
		 * channel.
		 *
		 * ---- Why the wrapper bus exists ----------------------------------
		 * bcm2835-mmc.c hands the engine a CPU-physical slave address:
		 *     host->bus_addr = iomem->start;                    / * :1422 * /
		 *     cfg.dst_addr   = host->bus_addr + SDHCI_BUFFER;   / * :1329 * /
		 * and bcm2835-dma.c turns it into a bus address with
		 *     dst = dma_map_resource(chan->device->dev, c->cfg.dst_addr, ...)
		 *                                                      / * :1026-1032 * /
		 * dma_map_resource() consults the DMA CONTROLLER device's
		 * dma_range_map, i.e. the dma-ranges of the bus this node sits under.
		 * translate_phys_to_dma() returns DMA_MAPPING_ERROR when no entry
		 * matches -- the kernel says so itself: "make sure dma_capable fails
		 * when no translation is available". soc_bus's dma-ranges covers only
		 * DomD bank1, so putting this node there would fail every transfer.
		 *
		 * Both dma-ranges entries below are COPIED VERBATIM from the host
		 * /soc node (dma-ranges = <0xc0000000 0x0 0x0 0x40000000
		 * 0x7c000000 0x0 0xfc000000 0x3800000>), re-expressed with this bus's
		 * 2 address cells:
		 *   peripherals  bus 0x7c000000 == cpu 0xfc000000, 0x3800000
		 *                -> dma_map_resource(0xfe300000) yields 0x7e300000
		 *   DRAM         bus 0xc0000000 == cpu 0x0, 0x40000000
		 *                -> the VideoCore alias, LOW 1 GiB ONLY
		 * Copying rather than reasoning matters here: the emmc2 note above
		 * records a board A/B where guessing this window wrong produced
		 * "mmc0: ADMA error: 0x02000000" retried forever and a silent
		 * rootwait hang. Measured on the board, channel 2 during a transfer
		 * holds SRC = 0x7e300020 (the SDHCI BUFFER as the VideoCore addresses
		 * it) and DST inside 0xc8000000..0xe0000000 (the bank1 alias window),
		 * and CS.ERROR is never set.
		 *
		 * ---- The hardware limit that remains (read this before tuning) ----
		 * This engine is a 32-bit master and only ever sees the low 1 GiB of
		 * DRAM through the alias above. Of DomD's three static-mem banks
		 * (bcm2711-raspberrypi4-64-xen.dtso: 0x40000000+0x40000000,
		 * 0x08000000+0x18000000, 0x80000000+0x20000000) ONLY bank1 is inside
		 * it, and DomD's `cma=` reservation takes most of it for vc4 and
		 * the decoder (256 of 384 MiB on 8 GiB, 336 of 416 MiB on 4 GiB,
		 * where swiotlb is cut to 16 MiB). Everything else is bounced by swiotlb
		 * (CONFIG_SWIOTLB=y, and SWIOTLB_XEN is def_bool y on ARM64+XEN), so
		 * the win over PIO is a memcpy trade, not a free ride -- and it is a
		 * win in INTERRUPTS, not in CPU time: a fixed 609 KB firmware load
		 * repeated three times cost 4487-6533 interrupts with this engine
		 * against 16105-16701 in PIO (about a third as many), while the CPU time
		 * was the same within noise. `dmesg | grep swiotlb` shows the bounce
		 * buffer and any "swiotlb buffer is full".
		 *
		 * ---- Why a SEPARATE bus and not soc_bus -------------------------
		 * of_dma_get_max_cpu_address() takes the MAX of cpu_addr+size WITHIN a
		 * node but the MIN ACROSS nodes (drivers/of/address.c). soc_bus
		 * supplies the tree minimum 0x1fffffff, which is what makes
		 * arm64_dma_phys_limit 0x20000000 and lands vc4's CMA inside bank1
		 * automatically (see the header note). This bus's own maximum is
		 * 0xff7fffff -- HIGHER -- so the tree minimum does not move and CMA
		 * placement is unchanged. Raising soc_bus's upper bound instead WOULD
		 * move it, and would break scanout.
		 *
		 * ---- Page 0xfe007000 is shared with dma40 -----------------------
		 * The legacy engine's registers (0xfe007000 + 0xb00) and dma40's
		 * (/scb/dma@7e007b00, 0xfe007b00 + 0x400) sit in the same 4 KiB page.
		 * Both engines are DomD's, so both nodes declare the page -- the
		 * second deliberate xen,reg duplicate in this file (header rules),
		 * forced the same way as vchiq's: each engine has its own SPIs
		 * (80-88 here, 89-92 there) and Xen routes IRQs only from a node that
		 * also carries xen,reg. The two register windows do not overlap, and
		 * the global DMA_ENABLE register at 0xfe007ff0 is the one word of
		 * genuinely shared state (measured 0x00007fff, i.e. channels 0..14
		 * all enabled): the engine is already enabled before DomD starts, and
		 * bcm2835-dma.c defines DMA_ENABLE but writes only per-channel
		 * registers, so neither driver instance has to touch it.
		 *
		 * In the DOM0_OS=linux flavour this node is stripped (below) and the
		 * legacy engine stays with Dom0 while dma40 is DomD's: the page is then
		 * shared ACROSS domains, which Xen does not police and which is benign
		 * for the same two reasons.
		 *
		 * Interrupts are copied exactly from the host, including the two lines
		 * that repeat: dma7/dma8 both raise SPI 87 and dma9/dma10 both raise
		 * SPI 88. bcm2835_dma_probe() looks each up by name and skips a
		 * channel whose IRQ is missing, so a partial set would still work --
		 * but there is no reason to trim it.
		 *
		 * INSIDE THE SD-STRIP BLOCK ON PURPOSE: mmcnr is stripped for
		 * DOM0_OS=linux (it shares SPI 126 with the emmc2 that Dom0-Linux
		 * owns), so its DMA engine goes with it. Leaving this node outside
		 * would hand a Linux Dom0's DMA controller to DomD for no user.
		 */
		legacy_dma_bus: legacy-dma-bus {
			compatible = "simple-bus";
			#address-cells = <0x2>;
			#size-cells = <0x2>;
			ranges;			/* MMIO stays identity */
			dma-ranges = <0x0 0x7c000000 0x0 0xfc000000 0x0 0x03800000>,
				     <0x0 0xc0000000 0x0 0x00000000 0x0 0x40000000>;

			dma_legacy: dma-controller@fe007000 {
				compatible = "brcm,bcm2835-dma";
				reg = <0x0 0xfe007000 0x0 0xb00>;
				interrupts = <0x0 80 0x4>,	/* dma0  */
					     <0x0 81 0x4>,	/* dma1  */
					     <0x0 82 0x4>,	/* dma2  */
					     <0x0 83 0x4>,	/* dma3  */
					     <0x0 84 0x4>,	/* dma4  */
					     <0x0 85 0x4>,	/* dma5  */
					     <0x0 86 0x4>,	/* dma6  */
					     <0x0 87 0x4>,	/* dma7  */
					     <0x0 87 0x4>,	/* dma8  (shares 87) */
					     <0x0 88 0x4>,	/* dma9  */
					     <0x0 88 0x4>;	/* dma10 (shares 88) */
				interrupt-names = "dma0", "dma1", "dma2", "dma3",
						  "dma4", "dma5", "dma6", "dma7",
						  "dma8", "dma9", "dma10";
				interrupt-parent = <&gic>;
				#dma-cells = <0x1>;
				brcm,dma-channel-mask = <0x7f5>;
				xen,path = "/soc/dma-controller@7e007000";
				xen,force-assign-without-iommu;
				xen,reg = <0x0 0xfe007000 0x0 0x1000 0x0 0xfe007000>;
				status = "okay";
			};
		};

		/*
		 * mmcnr's base clock. The host uses <&clocks BCM2835_CLOCK_EMMC>
		 * (cprman index 28) and cprman is not passed through -- same
		 * situation as emmc2 above. 250 MHz is not a guess: read in u-boot
		 * before Xen starts, CM_EMMCCTL (0xfe1011c0) = 0x00000296, i.e.
		 * SRC = 6 (plld_per), ENABLE = 1, BUSY = 1 -- the gate is already
		 * open -- and CM_EMMCDIV (0xfe1011c4) = 0x3000, DIVI = 3. The same
		 * read on EMMC2 gives DIVI = 7.5 against the 100 MHz declared for
		 * clk_emmc2, so plld_per = 750 MHz and both declared rates are
		 * exactly right.
		 */
		clk_mmcnr: clk-mmcnr {
			compatible = "fixed-clock";
			#clock-cells = <0x0>;
			clock-output-names = "mmcnr-clock";
			clock-frequency = <250000000>;	/* plld_per 750 / DIVI 3, measured */
		};

		/* ------------------------------------------------------------------
		 * mmcnr is the SDIO controller the on-board CYW43455 (BCM4345/6)
		 * Wi-Fi hangs off, and it is here because the Wi-Fi stack already in
		 * DomD -- brcmfmac, brcmfmac_cyw, brcmutil, cfg80211, wpa_supplicant,
		 * and the Cypress firmware when the build accepts synaptics-killswitch
		 * (README, *Wi-Fi firmware licence*) -- has no device to bind to
		 * without it.
		 * With this node the board reaches:
		 *
		 *     mmc1: SDHCI controller on fe300000.mmcnr
		 *     mmc1: new high speed SDIO card at address 0001
		 *     brcmfmac: Firmware: BCM4345/6 wl0: ... version 7.45.265 (CY)
		 *     wlan0  (up, scans return real APs)
		 *
		 * It shares GIC SPI 126 with emmc2, which is legal: IRQs are routed
		 * from the node xen,path resolves to in the HOST DT with virq == irq,
		 * and route_irq_to_guest() returns -EBUSY only for another domain, a
		 * different virq on the same line, or a line Xen itself uses. The hard
		 * requirement is the SAME trigger type in both nodes, because
		 * irq_set_spi_type() accepts a repeat only when curr == new. Both
		 * declare <0 126 4>. Linux is fine with the sharing: sdhci requests
		 * its IRQ with IRQF_SHARED.
		 *
		 * Against the host node /soc/mmcnr@7e300000 this keeps the
		 * compatible, replaces clocks, drops pinctrl-names, pinctrl-0
		 * and brcm,overclock-50, and adds brcm,board-type to wifi@1,
		 * all measured:
		 *
		 *   compatible  Kept in the host order, and NOT because
		 *               "brcm,bcm2835-mmc" is listed first: compatible order
		 *               only scores matches WITHIN one driver's
		 *               of_match_table, while which of two different builtin
		 *               drivers wins is decided by registration order, i.e.
		 *               link order, because of_platform_default_populate()
		 *               creates the device first and each driver binds the
		 *               first time it matches. Both are builtin here
		 *               (CONFIG_MMC_BCM2835_MMC=y, CONFIG_MMC_SDHCI_IPROC=y)
		 *               and drivers/mmc/host/Makefile puts bcm2835-mmc.o on
		 *               line 26 against sdhci-iproc.o on line 97, so
		 *               bcm2835-mmc.c registers first and takes it. That is
		 *               also why bare-metal Raspberry Pi OS -- same kernel,
		 *               same both-listed compatible -- gets bcm2835-mmc.
		 *               "brcm,bcm2835-sdhci" as the second entry is harmless
		 *               and preserves the sdhci-iproc fallback if
		 *               bcm2835-mmc is ever disabled.
		 *
		 *               With only "brcm,bcm2835-sdhci" the node binds
		 *               sdhci-iproc.c, whose bcm2835_data sets
		 *                   .caps = MAX_BLOCK | CAN_VDD_330 | CAN_DO_HISPD
		 *                   .missing_caps = true      / * :261-270 * /
		 *               and missing_caps makes probe pass those hardcoded
		 *               values to __sdhci_read_caps(host, NULL, &caps, &caps1)
		 *               (:395-396), so the capabilities register at 0x40 is
		 *               NEVER read. Neither CAN_DO_ADMA2 (bit 19) nor
		 *               CAN_DO_SDMA (bit 22) is in that list, so the
		 *               controller runs in PIO. The omission is deliberate
		 *               upstream -- the sibling iproc_data / iproc_cygnus_data
		 *               entries in the same file DO list both bits -- because
		 *               the BCM2835-family Arasan block has no usable internal
		 *               bus master. Raspberry Pi's answer is the downstream
		 *               bcm2835-mmc.c driver plus an EXTERNAL DMA engine,
		 *               which is what this compatible selects. See
		 *               legacy_dma_bus above, and note the fallback is safe:
		 *               if the channel cannot be acquired,
		 *               bcm2835_mmc_add_host() logs "Unable to initialise DMA
		 *               channel. Falling back to PIO" and clears have_dma
		 *               (bcm2835-mmc.c:1316).
		 *
		 *               THIS NODE STILL NEEDS NO dma-ranges WRAPPER:
		 *               bcm2835-mmc.c maps every buffer and slave address with
		 *               the DMA CONTROLLER's device, not its own --
		 *               dma_map_sg(dma_chan->device->dev, ...) at
		 *               bcm2835-mmc.c:522 and
		 *               dma_map_resource(chan->device->dev, ...) inside
		 *               bcm2835-dma.c:1026-1032. Wrapping mmcnr in the
		 *               VideoCore-alias bus would therefore buy nothing and
		 *               risk exactly the emmc2 failure documented above.
		 *
		 *   clocks      DROPPED and replaced: a fixed clock instead of cprman,
		 *               which is not passed through -- see clk_mmcnr.
		 *
		 *   pinctrl-0   DROPPED, with pinctrl-names. The host points at
		 *               <&sdio_pins> under gpio@7e200000 and DomD has
		 *               no GPIO controller. The firmware muxes GPIO
		 *               34-39 to ALT3 before Xen starts: GPFSEL3
		 *               (0xfe20000c) reads 0x3ffff000.
		 *
		 *   brcm,overclock-50  DROPPED. The host's value is 0, and 0 is
		 *               also what bcm2835-mmc.c uses when the property
		 *               is absent (no overclock).
		 *
		 * ADDED: wifi@1 carries brcm,board-type because brcmfmac otherwise derives it
		 * from the DT root's compatible (brcmf_of_probe -> of.c), and a Xen
		 * guest DT has no such property -- so it asks for the unsuffixed
		 * brcm/brcmfmac43455-sdio.bin, which meta-raspberrypi does not ship
		 * (only board-suffixed symlinks into cypress/). With the property the
		 * lookup hits brcmfmac43455-sdio.raspberrypi,4-model-b.bin and the
		 * firmware loads. No rootfs change needed.
		 * ------------------------------------------------------------------ */
		mmcnr: mmcnr@fe300000 {
			compatible = "brcm,bcm2835-mmc", "brcm,bcm2835-sdhci";
			reg = <0x0 0xfe300000 0x0 0x100>;
			interrupts = <0x0 126 0x4>;	/* GIC SPI 126, shared with emmc2 */
			interrupt-parent = <&gic>;
			clocks = <&clk_mmcnr>;
			/* The cell is a DREQ number, NOT a channel index
			 * (brcm,bcm2835-dma.yaml: "The single cell represents the DREQ
			 * number"). bcm2835_dma_xlate() takes any free channel from
			 * brcm,dma-channel-mask and only stores the DREQ, so DREQ 11
			 * does not need bit 11 in the mask. Value copied from the host
			 * mmcnr node.
			 *
			 * dma_request_slave_channel(dev, "rx-tx") resolves this from
			 * mmcnr's OWN node (bcm2835-mmc.c:1426), which is why the
			 * property lives here even though every dma_map_*() uses the DMA
			 * controller's device instead.
			 */
			dmas = <&dma_legacy 11>;
			dma-names = "rx-tx";
			bus-width = <0x4>;
			non-removable;
			#address-cells = <0x1>;
			#size-cells = <0x0>;
			xen,path = "/soc/mmcnr@7e300000";
			xen,force-assign-without-iommu;
			xen,reg = <0x0 0xfe300000 0x0 0x1000 0x0 0xfe300000>;
			status = "okay";

			brcmf: wifi@1 {
				reg = <0x1>;
				compatible = "brcm,bcm4329-fmac";
				brcm,board-type = "raspberrypi,4-model-b";
			};
		};
		/* SODEV-LINUX-DOM0-SD-STRIP-END */
	};
};
